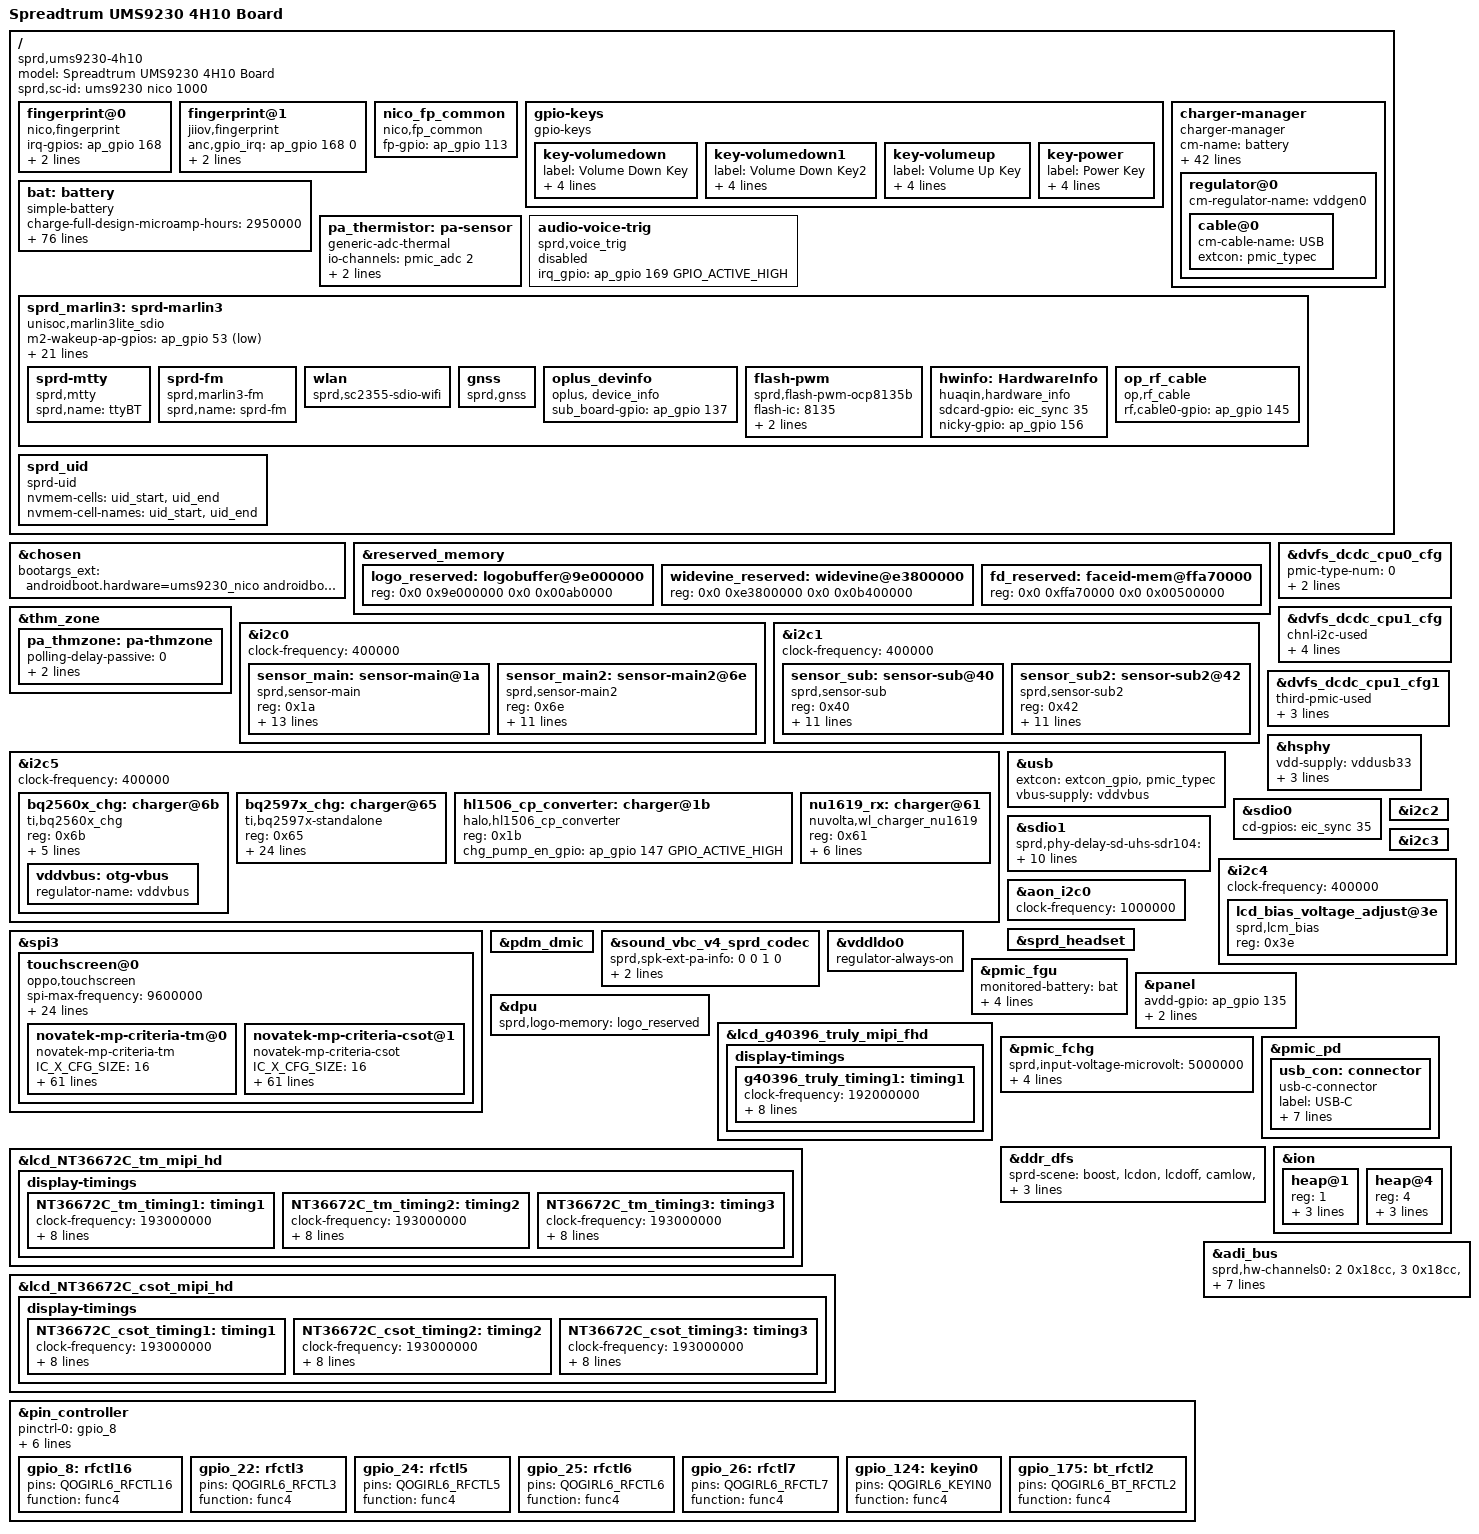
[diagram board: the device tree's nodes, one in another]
/dts-v1/;
/plugin/;
#include <dt-bindings/input/input.h>
#include <dt-bindings/gpio/gpio.h>
#include <dt-bindings/interrupt-controller/arm-gic.h>
#include <dt-bindings/clock/sprd,ums9230-clk.h>
#include <dt-bindings/mfd/sprd,sc2730-regs.h>
#include <dt-bindings/mfd/sprd,sc2730-mask.h>
#include <dt-bindings/usb/pd.h>
/*bsp.zhoulingyun 2022.04.04 modify for bring up lcd tm*/
#include "lcd/lcd_NT36672C_csot_mipi_hd.dtsi"
#include "lcd/lcd_NT36672C_tm_mipi_hd.dtsi"
#include "lcd/lcd_g40396_truly_mipi_fhd.dtsi"
#include "lcd/lcd_NT36672C_tm_mipi_hd_dummy.dtsi"
//#include "lcd/lcd_dummy_mipi.dtsi"

/ {

	model = "Spreadtrum UMS9230 4H10 Board";

	compatible = "sprd,ums9230-4h10";

	sprd,sc-id = "ums9230 nico 1000";
	fragment {
		target-path = "/";
		__overlay__ {
			#address-cells = <2>;
			#size-cells = <2>;
/*
			pwm_backlight: sprd_backlight {
				compatible = "sprd,sharkl6-backlight";
				pwms = <&pwms 2 40000>;
				pwm-names = "backlight";
				sprd,max-brightness-level = <924>;
				default-brightness-level = <262>;
				sprd,brightness-scale = <1023>;
				brightness-levels = <
							  0   3   4   5   6   7
					  8   9  10  11  12  13  14  16  17  18
					 19  20  21  22  23  24  25  26  27  28
					 29  31  33  35  37  39  41  43  45  47
					 48  50  52  54  56  58  60  62  64  67
					 69  72  74  76  78  80  82  84  86  88
					 90  92  94  96  98 100 102 104 107 109
					112 114 116 118 120 122 124 126 128 130
					132 134 136 138 140 142 144 147 149 151
					154 156 158 160 162 164 166 168 170 172
					175 178 181 184 187 190 193 196 199 203
					205 208 211 214 217 220 223 226 229 234
					237 240 243 247 250 253 256 259 263 266
					269 270 274 277 280 283 287 290 294 297
					300 303 307 310 314 318 325 329 334 339
					340 343 347 350 354 358 365 369 374 380
					382 385 389 392 396 400 407 411 416 422
					426 430 434 438 442 446 452 457 460 464
					470 474 480 486 492 498 504 508 512 516
					522 527 532 536 540 545 550 555 561 568
					574 579 584 589 594 600 605 610 615 620
					625 630 635 641 647 652 657 662 667 673
					688 694 700 706 712 716 720 725 730 735
					740 746 752 758 764 770 776 782 790 798
					803 810 817 825 832 840 845 850 855 861
					866 872 878 884 890 896 903 911 918 924
				>;
			};
*/
			fingerprint@0 {
				compatible = "nico,fingerprint";
				irq-gpios = <&ap_gpio 168 0 >;
				rst-gpios= <&ap_gpio 164 0 >;
				avdd-gpios = <&ap_gpio 122 0 >;
			};
			fingerprint@1 {
				compatible = "jiiov,fingerprint";
				anc,gpio_irq = <&ap_gpio 168 0>;
				anc,gpio_rst = <&ap_gpio 164 0>;
				anc,gpio_pwr = <&ap_gpio 122 0 >;
			}; 
			nico_fp_common {
				compatible = "nico,fp_common";
				fp-gpio = <&ap_gpio 113 0>;
			};
			gpio-keys {
				compatible = "gpio-keys";

				key-volumedown {
					label = "Volume Down Key";
					linux,code = <KEY_VOLUMEDOWN>;
					gpios = <&ap_gpio 124 GPIO_ACTIVE_LOW>;
					debounce-interval = <2>;
					wakeup-source;
				};

				key-volumedown1 {
					label = "Volume Down Key2";
					linux,code = <KEY_VOLUMEDOWN>;
					gpios = <&ap_gpio 125 GPIO_ACTIVE_LOW>;
					debounce-interval = <2>;
					wakeup-source;
				};

				key-volumeup {
					label = "Volume Up Key";
					linux,code = <KEY_VOLUMEUP>;
					gpios = <&pmic_eic 4 GPIO_ACTIVE_HIGH>;
					debounce-interval = <2>;
					wakeup-source;
				};

				key-power {
					label = "Power Key";
					linux,code = <KEY_POWER>;
					gpios = <&pmic_eic 1 GPIO_ACTIVE_LOW>;
					debounce-interval = <2>;
					wakeup-source;
				};
			};

			bat: battery {
				compatible = "simple-battery";
				charge-full-design-microamp-hours = <2950000>;
				charge-term-current-microamp = <60000>;
				constant-charge-voltage-max-microvolt = <4340000>;
				factory-internal-resistance-micro-ohms = <252000>;
				voltage-min-design-microvolt = <3450000>;
				fast-charge-threshold-microvolt = <4100000>;
				fullbatt-voltage = <4300000>;
				fullbatt-current = <120000>;
				fullbatt-track-end-vol = <4295000>;
				fullbatt-track-end-cur = <130000>;
				first-calib-voltage = <3580000>;
				first-calib-capacity = <50>;

				ir-cv-offset-microvolt = <100000>;
				ir-rc-micro-ohms = <20000>;
				ir-us-upper-limit-microvolt = <4500000>;

				ocv-capacity-celsius = <20>;
				ocv-capacity-table-0 = <4313000 100>, <4254000 95>, <4201000 90>,
							<4151000 85>, <4102000 80>, <4060000 75>,
							<4006000 70>, <3973000 65>, <3930000 60>,
							<3882000 55>, <3851000 50>, <3829000 45>,
							<3810000 40>, <3795000 35>, <3781000 30>,
							<3765000 25>, <3746000 20>, <3722000 15>,
							<3694000 10>, <3682000 5>, <3400000 0>;
				voltage-temp-table = <1084000 800>, <975000 850>, <868000 900>,
							  <765000 950>, <668000 1000>, <580000 1050>,
							  <501000 1100>, <430000 1150>, <369000 1200>,
							  <315000 1250>, <270000 1300>, <231000 1350>,
							  <197000 1400>, <169000 1450>, <145000 1500>,
							  <125000 1550>, <108000 1600>, <93000 1650>;
				capacity-temp-table = <45 100>, <25 100>, <10 100>, <0 95>, <(-10) 90>;
				resistance-temp-table = <45 53>, <25 100>, <10 395>, <0 567>, <(-10) 793>;
				charge-sdp-current-microamp = <500000 500000>;
				charge-dcp-current-microamp = <2000000 2500000>;
				charge-cdp-current-microamp = <1500000 1500000>;
				charge-unknown-current-microamp = <500000 500000>;
				charge-fchg-current-microamp = <3250000 3000000>;
				charge-flash-current-microamp = <5000000 2700000>;
				charge-wl-bpp-current-microamp = <1000000 1000000>;
				charge-wl-epp-current-microamp = <2000000 1000000>;

				dcp-jeita-temp-table = <1000 1030 0 4340000>, <1150 1180 700000 4340000>,
					<1450 1420 2000000 4340000>, <1600 1570 700000 4100000>;
				sdp-jeita-temp-table = <1000 1030 0 4340000>, <1150 1180 500000 4340000>,
					<1450 1420 500000 4340000>, <1600 1570 500000 4100000>;
				cdp-jeita-temp-table = <1000 1030 0 4340000>, <1150 1180 700000 4340000>,
					<1450 1420 1500000 4340000>, <1600 1570 700000 4100000>;
				unknown-jeita-temp-table = <1000 1030 0 4340000>, <1150 1180 500000 4340000>,
					<1450 1420 500000 4340000>, <1600 1570 500000 4100000>;
				fchg-jeita-temp-table = <1000 1030 0 4340000>, <1150 1180 700000 4340000>,
					<1450 1420 3250000 4340000>, <1600 1570 700000 4100000>;
				flash-jeita-temp-table = <1000 1030 0 4340000>, <1150 1180 1000000 4340000>,
					<1450 1420 5000000 4340000>, <1600 1570 1000000 4100000>;
				wl-bpp-jeita-temp-table = <1000 1030 0 4340000>, <1150 1180 500000 4340000>,
					<1450 1420 1000000 4340000>, <1600 1570 5000000 4100000>;
				wl-epp-jeita-temp-table = <1000 1030 0 4340000>, <1150 1180 500000 4340000>,
					<1450 1420 2000000 4340000>, <1600 1570 500000 4100000>;
				force-jeita-status = <2>;
			};

			charger-manager {
				compatible = "charger-manager";
				cm-name = "battery";
				cm-poll-mode = <2>;
				cm-poll-interval = <15000>;
				cm-battery-stat = <2>;

				cm-fullbatt-vchkdrop-ms = <30000>;
				cm-fullbatt-vchkdrop-volt = <60000>;
				cm-fullbatt-capacity = <100>;
				/*Charge pump target charge current*/
				cm-cp-taper-current = <1000000>;

				cm-num-chargers = <1>;
				cm-num-charge-pumps = <1>;
				cm-num-fast-chargers = <1>;
				cm-num-wireless-chargers = <1>;
				cm-num-wireless-charge-pump-converters = <1>;
				cm-chargers = "bq2560x_charger";
				cm-charge-pumps = "bq2597x-standalone";
				cm-fast-chargers = "sc2730_fast_charger";
				cm-wireless-chargers = "nu1619_wireless_charger";
				cm-wireless-charge-pump-converters = "hl1506_cp_converter";
				cm-fuel-gauge = "sc27xx-fgu";

				/* in deci centigrade */
				cm-battery-cold = <200>;
				cm-battery-cold-in-minus;
				cm-battery-hot = <800>;
				cm-battery-temp-diff = <100>;

				/* Allow charging for 6hr */
				cm-charging-max = <21600000>;
				/* recovery charging after stop charging 45min */
				cm-discharging-max = <2700000>;

				/* the interval to feed charger watchdog */
				cm-wdt-interval = <60>;

				/* drop voltage in microVolts to allow shutdown */
				cm-shutdown-voltage = <3100000>;

				/* when 99% of the time is exceeded, it will be forced to 100% */
				cm-tickle-time-out = <1500>;

				/* how much time to allow capacity change */
				cm-one-cap-time = <30>;
				/* cm-thermal-zone = "board-thmzone"; */
				/* when the safe charging voltage is exceeded, stop charging */
				cm-charge-voltage-max = <6500000>;
				cm-fast-charge-voltage-max = <10500000>;
				cm-flash-charge-voltage-max = <12000000>;
				cm-wireless-charge-voltage-max = <6500000>;
				cm-wireless-fast-charge-voltage-max = <12000000>;
				/* drop voltage in microVolts to restart charging */
				cm-charge-voltage-drop = <700000>;
				cm-fast-charge-voltage-drop = <700000>;
				cm-flash-charge-voltage-drop = <1000000>;
				cm-wireless-charge-voltage-drop = <700000>;
				cm-wireless-fast-charge-voltage-drop = <1000000>;

				cm-cap-remap-table = <1 2 3>, <2 3 2>, <98 99 2>, <99 100 3>;

				monitored-battery = <&bat>;

				regulator@0 {
					cm-regulator-name = "vddgen0";
					cable@0 {
						cm-cable-name = "USB";
						extcon = <&pmic_typec>;
					};
				};
			};
/*
			tboard_thermistor: thermal-sensor {
				compatible = "generic-adc-thermal";
				#thermal-sensor-cells = <0>;
				io-channels = <&pmic_adc 1>;
				io-channel-names = "sensor-channel";
				temperature-lookup-table = <
					(-39742) 1131
					(-29777) 1110
					(-19480) 1074
					(-4679) 983
					10110 838
					24805 654
					44922 413
					54903 316
					64895 238
					74884 178
					84883 133
					94883 100
					104880 75
					114889 57
					124872 43 >;
			};
*/
			pa_thermistor: pa-sensor {
				compatible = "generic-adc-thermal";
				#thermal-sensor-cells = <0>;
				io-channels = <&pmic_adc 2>;
				io-channel-names = "sensor-channel";
				temperature-lookup-table = <
					(-39742) 1131
					(-29777) 1110
					(-19480) 1074
					(-4679) 983
					10110 838
					24805 654
					44922 413
					54903 316
					64895 238
					74884 178
					84883 133
					94883 100
					104880 75
					114889 57
					124872 43 >;
			};
/*
			chg_thermistor: chg-sensor {
				compatible = "generic-adc-thermal";
				#thermal-sensor-cells = <0>;
				io-channels = <&pmic_adc 4>;
				io-channel-names = "sensor-channel";
				temperature-lookup-table = <
					(-39742) 1131
					(-29777) 1110
					(-19480) 1074
					(-4679) 983
					10110 838
					24805 654
					44922 413
					54903 316
					64895 238
					74884 178
					84883 133
					94883 100
					104880 75
					114889 57
					124872 43 >;
			};
*/
			audio-voice-trig {
				status = "disable";
				compatible = "sprd,voice_trig";
				irq_gpio = <&ap_gpio 169 GPIO_ACTIVE_HIGH>;
			};

			sprd_marlin3: sprd-marlin3 {
				compatible = "unisoc,marlin3lite_sdio";
				m2-wakeup-ap-gpios = <&ap_gpio 53 GPIO_ACTIVE_LOW>;
				reset-gpios = <&ap_gpio 177 GPIO_ACTIVE_LOW>;
				enable-gpios = <&ap_gpio 116 GPIO_ACTIVE_LOW>;
				m2-to-ap-irq-gpios = <&ap_gpio 52 GPIO_ACTIVE_LOW>;
				avdd12-supply = <&vddwcn>;
				avdd33-supply = <&vddwifipa>;
				dcxo18-supply = <&vddsim2>;
				xtal-26m-clk-type = "TSX";
				clock-names = "clk_32k","source","enable";
				clocks = <&aon_clk CLK_AUX2>,
					 <&ext_32k>,
					 <&aonapb_gate CLK_AUX2_EB>;

				extcon = <&sdio1>;
				sdhci-name = <&sdio1>;
				sprd,btwf-file-name = "/dev/block/by-name/wcnmodem";
				sprd,gnss-file-name = "/vendor/firmware/gnssmodem.bin";
				adma-tx;
				adma-rx;

				/*
				 * bound parameter:
				 * [0]:addr offset, [1]:mask, [2]:unboundval, [3]:boundval
				 */
				//avdd12-parent-bound-chip = <REG_ANA_SLP_DCDC_PD_CTRL MASK_ANA_SLP_DCDCGEN1_PD_EN 0x0 MASK_ANA_SLP_DCDCGEN1_PD_EN>;
				avdd12-bound-wbreq = <REG_ANA_LDO_XTL_EN10 MASK_ANA_LDO_VDDWCN_EXT_XTL3_EN 0x0 MASK_ANA_LDO_VDDWCN_EXT_XTL3_EN>;
				avdd33-bound-wbreq = <REG_ANA_LDO_XTL_EN11 MASK_ANA_LDO_VDDWIFIPA_EXT_XTL3_EN 0x0 MASK_ANA_LDO_VDDWIFIPA_EXT_XTL3_EN>;

				sprd-mtty {
					compatible = "sprd,mtty";
					sprd,name = "ttyBT";
				};

				sprd-fm {
					compatible = "sprd,marlin3-fm";
					sprd,name = "sprd-fm";
				};

				wlan {
					compatible = "sprd,sc2355-sdio-wifi";
				};

				gnss {
					compatible = "sprd,gnss";
				};

				/*Used to show hardware information for oplus factory mode*/
				oplus_devinfo:oplus_devinfo {
					compatible = "oplus, device_info";
					sub_board-gpio = <&ap_gpio 137 0>;
					status = "okay";
				};
				
				flash-pwm {
					compatible = "sprd,flash-pwm-ocp8135b";
					flash-ic = <8135>;
					pwms = <&pwms 0 50000>;
					flash-en-gpios = <&ap_gpio 139 0>;
					status = "okay";
				};
				
				/*Used to show hardware information for hq factory mode*/
				hwinfo:HardwareInfo {
					compatible = "huaqin,hardware_info";
					sdcard-gpio = <&eic_sync 35 0>;
					nicky-gpio  = <&ap_gpio 156 0>;
					status = "okay";
				};

				/*Used to check the RF antenna*/
				op_rf_cable {
					compatible = "op,rf_cable";
					status = "okay";
					rf,cable0-gpio = <&ap_gpio 145 0>;
				};
			};

			sprd_uid {
				compatible = "sprd-uid";
				nvmem-cells = <&uid_start>, <&uid_end>;
				nvmem-cell-names = "uid_start", "uid_end";
			};
		};
	};
};

&chosen {
	bootargs_ext = "androidboot.hardware=ums9230_nico androidboot.dtbo_idx=0";
};

&reserved_memory {
	#address-cells = <2>;
	#size-cells = <2>;
	logo_reserved: logobuffer@9e000000{
		reg = <0x0 0x9e000000 0x0 0x00ab0000>;
	};

	widevine_reserved: widevine@e3800000 {
		reg = <0x0 0xe3800000 0x0 0x0b400000>;
	};

	fd_reserved: faceid-mem@ffa70000 {
		reg = <0x0 0xffa70000 0x0 0x00500000>;
	};
};

&thm_zone {
/*
	bd_thmzone: board-thmzone {
		polling-delay-passive = <0>;
		polling-delay = <0>;
		thermal-sensors = <&tboard_thermistor>;
	};
*/
	pa_thmzone: pa-thmzone {
		polling-delay-passive = <0>;
		polling-delay = <0>;
		thermal-sensors = <&pa_thermistor>;
	};
/*
	chg_thmzone: chg-thmzone {
		polling-delay-passive = <0>;
		polling-delay = <0>;
		thermal-sensors = <&chg_thermistor>;
	};
*/
};

&i2c0 {
	status = "okay";
	clock-frequency = <400000>;
	#address-cells = <1>;
	#size-cells = <0>;

	sensor_main: sensor-main@1a {
		compatible = "sprd,sensor-main";
		reg = <0x1a>;
		clock-names = "clk_src","sensor_eb",
			"clk_96m","clk_76m8",
			"clk_48m","clk_26m";
		clocks = <&mm_clk CLK_SENSOR0>,<&mm_gate CLK_MM_SENSOR0_EB>,
				<&pll1 CLK_TWPLL_96M>,<&pll1 CLK_TWPLL_76M8>,
				<&pll1 CLK_TWPLL_48M>,<&ext_26m>;
		vddio-supply = <&vddcamio>;
		vddcama-supply = <&vddcama0>;
		vddcamd-supply = <&vddcamd0>;
		vddcammot-supply = <&vddcammot>;
		reset-gpios = <&ap_gpio 44 0>;
		dvdd-gpios = <&ap_gpio 82 0>;
		sprd,phyid = <2>;
		csi = <&csi0>;
		power-domains = <&mm_domain>;
	};

	sensor_main2: sensor-main2@6e {//macro
		compatible = "sprd,sensor-main2";
		reg = <0x6e>;
		clock-names = "clk_src","sensor_eb",
			"clk_96m","clk_76m8",
			"clk_48m","clk_26m";
		clocks = <&mm_clk CLK_SENSOR2>,<&mm_gate CLK_MM_SENSOR2_EB>,
				<&pll1 CLK_TWPLL_96M>,<&pll1 CLK_TWPLL_76M8>,
				<&pll1 CLK_TWPLL_48M>,<&ext_26m>;
		vddio-supply = <&vddcamio>;
		vddcama-supply = <&vddldo1>;
		sprd,vddldo1-voltage = <2800000>;
		reset-gpios = <&ap_gpio 45 0>;
		sprd,phyid = <4>;
		csi = <&csi1>;
		power-domains = <&mm_domain>;
		};
};

&i2c1 {
	status = "okay";
	clock-frequency = <400000>;
	#address-cells = <1>;
	#size-cells = <0>;

	sensor_sub: sensor-sub@40 {
		compatible = "sprd,sensor-sub";
		reg = <0x40>;
		clock-names = "clk_src","sensor_eb",
			"clk_96m","clk_76m8",
			"clk_48m","clk_26m";
		clocks = <&mm_clk CLK_SENSOR1>,<&mm_gate CLK_MM_SENSOR1_EB>,
				<&pll1 CLK_TWPLL_96M>,<&pll1 CLK_TWPLL_76M8>,
				<&pll1 CLK_TWPLL_48M>,<&ext_26m>;
		vddio-supply = <&vddcamio>;
		vddcama-supply = <&vddcama1>;
		vddcamd-supply = <&vddcamd1>;
	/*	dvdd-gpios = <&ap_gpio 137 0>;*/
	/*	vddcammot-supply = <&vddcammot>;*/
		reset-gpios = <&ap_gpio 41 0>;
	/*	power-down-gpios = <&ap_gpio 46 0>;*/
	/*	mipi-switch-en-gpios = <&ap_gpio 55 0>;*/
	/*	mipi-switch-mode-gpios = <&ap_gpio 8 0>;*/
		sprd,phyid = <0>;
		csi = <&csi0>;
		power-domains = <&mm_domain>;
	};

		sensor_sub2: sensor-sub2@42 {//vga
		compatible = "sprd,sensor-sub2";
		reg = <0x42>;
		clock-names = "clk_src","sensor_eb",
			"clk_96m","clk_76m8",
			"clk_48m","clk_26m";
		clocks = <&mm_clk CLK_SENSOR2>,<&mm_gate CLK_MM_SENSOR2_EB>,
				<&pll1 CLK_TWPLL_96M>,<&pll1 CLK_TWPLL_76M8>,
				<&pll1 CLK_TWPLL_48M>,<&ext_26m>;
		vddio-supply = <&vddcamio>;
		vddcama-supply = <&vddldo1>;
		sprd,vddldo1-voltage = <2800000>;
		reset-gpios = <&ap_gpio 40 0>;
		sprd,phyid = <3>;
		csi = <&csi1>;
		power-domains = <&mm_domain>;
	};
};

&i2c5 {
	status = "okay";
	clock-frequency = <400000>;
	#address-cells = <1>;
	#size-cells = <0>;

	bq2560x_chg: charger@6b {
		compatible = "ti,bq2560x_chg";
		reg = <0x6b>;
		phys = <&hsphy>;
		monitored-battery = <&bat>;
		extcon = <&pmic_typec>, <&pmic_pd>;
		pd-extcon-enable;
		irq-gpio = <&ap_gpio 115 GPIO_ACTIVE_LOW>;
		vddvbus:otg-vbus {
			regulator-name = "vddvbus";
		};
	};

	bq2597x_chg: charger@65 {
		compatible = "ti,bq2597x-standalone";
		reg = <0x65>;
		irq-gpio = <&ap_gpio 126 GPIO_ACTIVE_LOW>;

		ti,bq2597x,bus-therm-disable = <1>;
		ti,bq2597x,regulation-disable = <1>;

		ti,bq2597x,bat-ovp-threshold = <4400>;
		ti,bq2597x,bat-ovp-alarm-threshold = <4340>;
		ti,bq2597x,bat-ocp-threshold = <5500>;
		ti,bq2597x,bat-ocp-alarm-threshold = <5000>;
		ti,bq2597x,bus-ovp-threshold = <11500>;
		ti,bq2597x,bus-ovp-alarm-threshold = <10500>;
		ti,bq2597x,bus-ocp-threshold = <3000>;
		ti,bq2597x,bus-ocp-alarm-threshold = <2700>;
		ti,bq2597x,bat-ucp-alarm-threshold = <1000>;
		ti,bq2597x,bat-therm-threshold = <0x15>;
		ti,bq2597x,bus-therm-threshold = <0x15>;
		ti,bq2597x,die-therm-threshold = <0xc8>;
		ti,bq2597x,ac-ovp-threshold = <11>;
		ti,bq2597x,sense-resistor-mohm = <5>;
		ti,bq2597x,adc-sample-bits = <13>;
		ti,bq2597x,ibat-regulation-threshold = <300>;
		ti,bq2597x,vbat-regulation-threshold = <100>;
		ti,bq2597x,vdrop-threshold = <400>;
		ti,bq2597x,vdrop-deglitch = <5000>;
		ti,bq2597x,ss-timeout = <100000>;
		ti,bq2597x,watchdog-timer = <30000>;
	};

	hl1506_cp_converter: charger@1b {
		compatible = "halo,hl1506_cp_converter";
		reg = <0x1b>;
		chg_pump_en_gpio = <&ap_gpio 147 GPIO_ACTIVE_HIGH>;
	};

	nu1619_rx: charger@61 {
		compatible = "nuvolta,wl_charger_nu1619";
		reg = <0x61>;
		phys = <&hsphy>;
		rx,irq_gpio = <&ap_gpio 146 GPIO_ACTIVE_LOW>;
		switch_chg_en_gpio = <&ap_gpio 171 GPIO_ACTIVE_HIGH>;
		switch_flag_en_gpio = <&ap_gpio 176 GPIO_ACTIVE_HIGH>;
	};

};



&spi3 {
	status = "okay";
	#address-cells = <1>;
	#size-cells = <0>;


	touchscreen@0 {
			compatible = "oppo,touchscreen";
			spi-max-frequency = <9600000>;
			reg = <0>;
			/*touch,irq-gpio = <&ap_gpio 144 GPIO_ACTIVE_HIGH>;*/
			touch,irq-gpio = <&eic_async 16 GPIO_ACTIVE_HIGH>;
			touch,rst-gpio = <&ap_gpio 146 GPIO_ACTIVE_HIGH>;
			touch,panel-coords = <0 720 0 1600>;
			chipone,x-res = <720>;
			chipone,y-res = <1600>;

			chipone,test-reset-pin;
            chipone,test-rawdata;
            chipone,test-rawdata-frames = <1>;
            chipone,rawdata-min = <1500>;//base 2500*40%
            chipone,rawdata-max = <3500>;
            chipone,test-noise;
            chipone,test-noise-frames = <50>;
            chipone,noise-max = <70>;
            chipone,test-open;
            chipone,open-min = <3000>;
            chipone,test-short;
            chipone,short-min = <500>;
            chipone,test-compensate-cap;
            chipone,compensate-cap-min = <1>;
            chipone,compensate-cap-max = <126>;
			himax,display-coords = <0 720 0 1600>;

		//for novatek
		//novatek,pen-support;
		//novatek,stylus-resol-double;

		/* 525 */
		//novatek,swrst-n8-addr = <0x01F01A>;

		/* 672A, 525B, 675, 526, 672C, 523 */
		novatek,swrst-n8-addr = <0x03F0FE>;
		//novatek,spi-rd-fast-addr = <0x03F310>;

		/* MP */
		novatek,mp-support-dt;

		/* MP Criteria For TM */
		novatek-mp-criteria-tm@0 {
			#address-cells = <1>;
			#size-cells = <0>;
			compatible = "novatek-mp-criteria-tm";

			/* MP Config */
			IC_X_CFG_SIZE = <16>;
			IC_Y_CFG_SIZE = <36>;
			IC_KEY_CFG_SIZE = <4>;
			X_Channel = <16>;
			Y_Channel = <36>;
			AIN_X = <0 1 2 3 4 5 6 7 8 9 10 11 12 13 14 15>;
			AIN_Y = <0 1 2 3 4 5 6 7 8 9 10 11 12 13 14 15 16 17 18 19 20 21 22 23 24 25 26 27 28 29 30 31 32 33 34 35>;
			AIN_KEY = <0 1 2 0xFF>;

			/* MP Criteria */
			PS_Config_Lmt_Short_Rawdata_P = <
				14008 14008 14008 14008 14008 14008 14008 14008 14008 14008 14008 14008 14008 14008 14008 14008
				14008 14008 14008 14008 14008 14008 14008 14008 14008 14008 14008 14008 14008 14008 14008 14008
				14008 14008 14008 14008 14008 14008 14008 14008 14008 14008 14008 14008 14008 14008 14008 14008
				14008 14008 14008 14008 14008 14008 14008 14008 14008 14008 14008 14008 14008 14008 14008 14008
				14008 14008 14008 14008 14008 14008 14008 14008 14008 14008 14008 14008 14008 14008 14008 14008
				14008 14008 14008 14008 14008 14008 14008 14008 14008 14008 14008 14008 14008 14008 14008 14008
				14008 14008 14008 14008 14008 14008 14008 14008 14008 14008 14008 14008 14008 14008 14008 14008
				14008 14008 14008 14008 14008 14008 14008 14008 14008 14008 14008 14008 14008 14008 14008 14008
				14008 14008 14008 14008 14008 14008 14008 14008 14008 14008 14008 14008 14008 14008 14008 14008
				14008 14008 14008 14008 14008 14008 14008 14008 14008 14008 14008 14008 14008 14008 14008 14008
				14008 14008 14008 14008 14008 14008 14008 14008 14008 14008 14008 14008 14008 14008 14008 14008
				14008 14008 14008 14008 14008 14008 14008 14008 14008 14008 14008 14008 14008 14008 14008 14008
				14008 14008 14008 14008 14008 14008 14008 14008 14008 14008 14008 14008 14008 14008 14008 14008
				14008 14008 14008 14008 14008 14008 14008 14008 14008 14008 14008 14008 14008 14008 14008 14008
				14008 14008 14008 14008 14008 14008 14008 14008 14008 14008 14008 14008 14008 14008 14008 14008
				14008 14008 14008 14008 14008 14008 14008 14008 14008 14008 14008 14008 14008 14008 14008 14008
				14008 14008 14008 14008 14008 14008 14008 14008 14008 14008 14008 14008 14008 14008 14008 14008
				14008 14008 14008 14008 14008 14008 14008 14008 14008 14008 14008 14008 14008 14008 14008 14008
				14008 14008 14008 14008 14008 14008 14008 14008 14008 14008 14008 14008 14008 14008 14008 14008
				14008 14008 14008 14008 14008 14008 14008 14008 14008 14008 14008 14008 14008 14008 14008 14008
				14008 14008 14008 14008 14008 14008 14008 14008 14008 14008 14008 14008 14008 14008 14008 14008
				14008 14008 14008 14008 14008 14008 14008 14008 14008 14008 14008 14008 14008 14008 14008 14008
				14008 14008 14008 14008 14008 14008 14008 14008 14008 14008 14008 14008 14008 14008 14008 14008
				14008 14008 14008 14008 14008 14008 14008 14008 14008 14008 14008 14008 14008 14008 14008 14008
				14008 14008 14008 14008 14008 14008 14008 14008 14008 14008 14008 14008 14008 14008 14008 14008
				14008 14008 14008 14008 14008 14008 14008 14008 14008 14008 14008 14008 14008 14008 14008 14008
				14008 14008 14008 14008 14008 14008 14008 14008 14008 14008 14008 14008 14008 14008 14008 14008
				14008 14008 14008 14008 14008 14008 14008 14008 14008 14008 14008 14008 14008 14008 14008 14008
				14008 14008 14008 14008 14008 14008 14008 14008 14008 14008 14008 14008 14008 14008 14008 14008
				14008 14008 14008 14008 14008 14008 14008 14008 14008 14008 14008 14008 14008 14008 14008 14008
				14008 14008 14008 14008 14008 14008 14008 14008 14008 14008 14008 14008 14008 14008 14008 14008
				14008 14008 14008 14008 14008 14008 14008 14008 14008 14008 14008 14008 14008 14008 14008 14008
				14008 14008 14008 14008 14008 14008 14008 14008 14008 14008 14008 14008 14008 14008 14008 14008
				14008 14008 14008 14008 14008 14008 14008 14008 14008 14008 14008 14008 14008 14008 14008 14008
				14008 14008 14008 14008 14008 14008 14008 14008 14008 14008 14008 14008 14008 14008 14008 14008
				14008 14008 14008 14008 14008 14008 14008 14008 14008 14008 14008 14008 14008 14008 14008 14008
				>;

			PS_Config_Lmt_Short_Rawdata_N = <
				10100 10100 10100 10100 10100 10100 10100 10100 10100 10100 10100 10100 10100 10100 10100 10100
				10100 10100 10100 10100 10100 10100 10100 10100 10100 10100 10100 10100 10100 10100 10100 10100
				10100 10100 10100 10100 10100 10100 10100 10100 10100 10100 10100 10100 10100 10100 10100 10100
				10100 10100 10100 10100 10100 10100 10100 10100 10100 10100 10100 10100 10100 10100 10100 10100
				10100 10100 10100 10100 10100 10100 10100 10100 10100 10100 10100 10100 10100 10100 10100 10100
				10100 10100 10100 10100 10100 10100 10100 10100 10100 10100 10100 10100 10100 10100 10100 10100
				10100 10100 10100 10100 10100 10100 10100 10100 10100 10100 10100 10100 10100 10100 10100 10100
				10100 10100 10100 10100 10100 10100 10100 10100 10100 10100 10100 10100 10100 10100 10100 10100
				10100 10100 10100 10100 10100 10100 10100 10100 10100 10100 10100 10100 10100 10100 10100 10100
				10100 10100 10100 10100 10100 10100 10100 10100 10100 10100 10100 10100 10100 10100 10100 10100
				10100 10100 10100 10100 10100 10100 10100 10100 10100 10100 10100 10100 10100 10100 10100 10100
				10100 10100 10100 10100 10100 10100 10100 10100 10100 10100 10100 10100 10100 10100 10100 10100
				10100 10100 10100 10100 10100 10100 10100 10100 10100 10100 10100 10100 10100 10100 10100 10100
				10100 10100 10100 10100 10100 10100 10100 10100 10100 10100 10100 10100 10100 10100 10100 10100
				10100 10100 10100 10100 10100 10100 10100 10100 10100 10100 10100 10100 10100 10100 10100 10100
				10100 10100 10100 10100 10100 10100 10100 10100 10100 10100 10100 10100 10100 10100 10100 10100
				10100 10100 10100 10100 10100 10100 10100 10100 10100 10100 10100 10100 10100 10100 10100 10100
				10100 10100 10100 10100 10100 10100 10100 10100 10100 10100 10100 10100 10100 10100 10100 10100
				10100 10100 10100 10100 10100 10100 10100 10100 10100 10100 10100 10100 10100 10100 10100 10100
				10100 10100 10100 10100 10100 10100 10100 10100 10100 10100 10100 10100 10100 10100 10100 10100
				10100 10100 10100 10100 10100 10100 10100 10100 10100 10100 10100 10100 10100 10100 10100 10100
				10100 10100 10100 10100 10100 10100 10100 10100 10100 10100 10100 10100 10100 10100 10100 10100
				10100 10100 10100 10100 10100 10100 10100 10100 10100 10100 10100 10100 10100 10100 10100 10100
				10100 10100 10100 10100 10100 10100 10100 10100 10100 10100 10100 10100 10100 10100 10100 10100
				10100 10100 10100 10100 10100 10100 10100 10100 10100 10100 10100 10100 10100 10100 10100 10100
				10100 10100 10100 10100 10100 10100 10100 10100 10100 10100 10100 10100 10100 10100 10100 10100
				10100 10100 10100 10100 10100 10100 10100 10100 10100 10100 10100 10100 10100 10100 10100 10100
				10100 10100 10100 10100 10100 10100 10100 10100 10100 10100 10100 10100 10100 10100 10100 10100
				10100 10100 10100 10100 10100 10100 10100 10100 10100 10100 10100 10100 10100 10100 10100 10100
				10100 10100 10100 10100 10100 10100 10100 10100 10100 10100 10100 10100 10100 10100 10100 10100
				10100 10100 10100 10100 10100 10100 10100 10100 10100 10100 10100 10100 10100 10100 10100 10100
				10100 10100 10100 10100 10100 10100 10100 10100 10100 10100 10100 10100 10100 10100 10100 10100
				10100 10100 10100 10100 10100 10100 10100 10100 10100 10100 10100 10100 10100 10100 10100 10100
				10100 10100 10100 10100 10100 10100 10100 10100 10100 10100 10100 10100 10100 10100 10100 10100
				10100 10100 10100 10100 10100 10100 10100 10100 10100 10100 10100 10100 10100 10100 10100 10100
				10100 10100 10100 10100 10100 10100 10100 10100 10100 10100 10100 10100 10100 10100 10100 10100
				>;

			PS_Config_Lmt_Open_Rawdata_P = <
				1692 1716 1733 1752 1741 1741 1726 65535 65535 1675 1687 1703 1717 1717 1696 1696
				1670 1687 1709 1736 1730 1727 1726 1694 1642 1696 1691 1708 1722 1715 1691 1702
				1652 1681 1702 1731 1727 1723 1724 1706 1664 1712 1712 1727 1745 1730 1712 1722
				1709 1720 1750 1785 1778 1773 1775 1755 1705 1734 1730 1747 1759 1741 1722 1730
				1754 1752 1787 1825 1814 1811 1808 1792 1769 1785 1792 1811 1817 1800 1782 1794
				1758 1772 1789 1825 1817 1815 1813 1794 1752 1785 1769 1790 1796 1778 1759 1772
				1776 1793 1810 1842 1836 1836 1828 1814 1750 1779 1766 1783 1783 1772 1747 1768
				1800 1822 1825 1870 1869 1870 1862 1845 1804 1834 1806 1835 1831 1814 1790 1807
				1807 1825 1846 1869 1873 1870 1862 1842 1825 1852 1841 1849 1839 1825 1804 1820
				1836 1860 1877 1888 1906 1905 1899 1871 1838 1866 1852 1848 1849 1834 1807 1829
				1856 1878 1895 1926 1919 1923 1911 1890 1864 1897 1884 1898 1873 1862 1832 1856
				1873 1902 1916 1946 1927 1944 1932 1905 1894 1926 1909 1925 1880 1881 1853 1874
				1864 1892 1908 1937 1940 1940 1926 1898 1880 1909 1898 1909 1878 1867 1838 1862
				1869 1899 1922 1947 1954 1948 1936 1904 1881 1909 1898 1911 1876 1856 1832 1859
				1897 1927 1943 1968 1974 1957 1954 1922 1927 1954 1939 1957 1922 1888 1874 1901
				1913 1948 1962 1989 2000 1997 1979 1946 1955 1976 1962 1978 1937 1916 1884 1906
				1913 1948 1953 1983 1995 1996 1957 1940 1944 1972 1955 1975 1933 1918 1866 1916
				1933 1974 1979 2007 2023 2024 2007 1965 1989 2016 1997 2014 1971 1951 1915 1946
				1958 1927 1919 1922 1897 1894 1883 1877 1838 1901 1890 1898 1898 1911 1902 1919
				1974 1947 1934 1939 1916 1915 1902 1887 1866 1929 1918 1932 1930 1943 1932 1937
				1972 1951 1941 1947 1926 1922 1912 1909 1856 1912 1906 1920 1918 1934 1919 1930
				1981 1961 1953 1958 1933 1929 1920 1912 1883 1941 1936 1948 1946 1960 1947 1958
				1993 1982 1968 1971 1953 1944 1930 1926 1899 1957 1947 1967 1964 1974 1958 1971
				1999 1989 1979 1986 1960 1955 1944 1939 1890 1943 1940 1958 1955 1962 1950 1964
				1983 1978 1967 1975 1950 1943 1930 1923 1898 1953 1946 1965 1962 1974 1960 1974
				2030 2027 2013 2021 1999 1995 1981 1975 1908 1957 1951 1971 1968 1979 1962 1972
				2002 2002 1992 2002 1974 1969 1957 1950 1894 1944 1939 1958 1955 1964 1954 1958
				2014 2018 2013 2021 1995 1993 1983 1976 1926 1974 1967 1988 1982 1996 1981 1986
				2030 2041 2027 2041 2007 2004 1990 1981 1940 1990 1982 2007 2000 2014 1999 2006
				2025 2034 2027 2039 2009 2007 1996 1983 1943 1990 1982 2004 1999 2013 1996 2003
				2016 2037 2025 2032 2003 2000 1988 1976 1912 1964 1958 1975 1971 1988 1965 1972
				2044 2066 2058 2066 2038 2041 2023 2010 1964 2016 2003 2024 2020 2037 2014 2018
				2017 2038 2035 2042 2017 2016 1999 1985 1939 1988 1978 1996 1992 2006 1981 1988
				2025 2049 2046 2058 2028 2031 2014 1999 1969 2017 2002 2023 2016 2031 2002 2010
				1978 2021 2020 2032 2002 2003 1988 1972 1948 1997 1981 2004 1999 2016 1982 1978
				1820 1876 1971 2052 2020 2020 2002 1986 1974 2027 2010 2035 2032 1988 1867 1829
				>;

			PS_Config_Lmt_Open_Rawdata_N = <
				725 735 742 751 746 746 739 (-65535) (-65535) 718 723 730 736 736 727 727
				715 723 732 744 741 740 739 726 703 727 724 732 738 735 724 729
				708 720 729 742 740 738 739 731 713 733 733 740 748 741 733 738
				732 737 750 765 762 760 760 752 730 743 741 748 754 746 738 741
				751 751 766 782 777 776 775 768 758 765 768 776 778 771 763 769
				753 759 766 782 778 778 777 769 751 765 758 767 769 762 754 759
				761 768 775 789 787 787 783 777 750 762 757 764 764 759 748 757
				771 781 782 801 801 801 798 790 773 786 774 786 784 777 767 774
				774 782 791 801 802 801 798 789 782 793 789 792 788 782 773 780
				787 797 804 809 817 816 814 802 787 799 793 792 792 786 774 784
				795 805 812 825 822 824 819 810 799 813 807 813 802 798 785 795
				802 815 821 834 826 833 828 816 811 825 818 825 805 806 794 803
				799 811 817 830 831 831 825 813 805 818 813 818 805 800 787 798
				801 814 823 834 837 835 829 816 806 818 813 819 804 795 785 796
				813 826 832 843 846 838 837 823 826 837 831 838 823 809 803 814
				820 835 841 852 857 856 848 834 838 847 841 847 830 821 807 817
				820 835 837 850 855 855 838 831 833 845 838 846 828 822 799 821
				828 846 848 860 867 867 860 842 852 864 856 863 844 836 820 834
				839 826 822 823 813 811 807 804 787 814 810 813 813 819 815 822
				846 834 829 831 821 820 815 808 799 826 822 828 827 832 828 830
				845 836 832 834 825 823 819 818 795 819 817 823 822 829 822 827
				849 840 837 839 828 826 823 819 807 832 829 835 834 840 834 839
				854 849 843 844 837 833 827 825 814 838 834 843 841 846 839 844
				856 852 848 851 840 838 833 831 810 832 831 839 838 841 835 841
				850 847 843 846 835 832 827 824 813 837 834 842 841 846 840 846
				870 868 862 866 856 855 849 846 817 838 836 844 843 848 841 845
				858 858 853 858 846 844 838 835 811 833 831 839 838 841 837 839
				863 865 862 866 855 854 850 847 825 846 843 852 849 855 849 851
				870 874 868 874 860 859 853 849 831 853 849 860 857 863 856 859
				868 871 868 874 861 860 855 850 832 853 849 859 856 862 855 858
				864 873 868 871 858 857 852 847 819 841 839 846 844 852 842 845
				876 885 882 885 873 874 867 861 841 864 858 867 865 873 863 865
				864 873 872 875 864 864 856 850 831 852 847 855 853 859 849 852
				868 878 877 882 869 870 863 856 844 864 858 867 864 870 858 861
				847 866 865 871 858 858 852 845 835 856 849 859 856 864 849 847
				780 804 844 879 865 865 858 851 846 868 861 872 871 852 800 784
				>;

			PS_Config_Lmt_FW_Rawdata_P = <
				1138 1120 1107 1107 1108 1100 1111 65535 65535 1125 1107 1120 1111 1103 1107 1125
				1113 1110 1106 1103 1118 1107 1115 1115 1121 1107 1107 1107 1111 1108 1107 1127
				1118 1111 1110 1114 1093 1108 1103 1110 1120 1115 1114 1106 1115 1113 1110 1124
				1122 1090 1096 1100 1090 1092 1089 1104 1115 1118 1113 1104 1108 1111 1110 1110
				1113 1108 1108 1121 1104 1111 1107 1106 1099 1100 1096 1094 1097 1099 1099 1108
				1103 1108 1111 1090 1111 1103 1106 1097 1114 1111 1108 1107 1121 1118 1121 1092
				1114 1110 1118 1124 1114 1128 1118 1122 1111 1111 1115 1113 1122 1124 1121 1110
				1134 1100 1101 1106 1101 1106 1100 1121 1107 1108 1114 1115 1117 1111 1115 1110
				1090 1076 1089 1080 1096 1090 1096 1086 1108 1111 1124 1120 1117 1117 1117 1099
				1107 1129 1125 1125 1124 1117 1131 1106 1142 1135 1122 1125 1117 1114 1120 1108
				1115 1106 1120 1129 1106 1118 1106 1108 1099 1103 1107 1099 1099 1090 1097 1115
				1101 1122 1115 1122 1100 1121 1110 1103 1113 1117 1110 1108 1107 1104 1110 1124
				1128 1134 1131 1128 1121 1129 1121 1120 1120 1121 1117 1114 1113 1114 1107 1114
				1113 1097 1101 1113 1103 1111 1115 1113 1108 1101 1093 1100 1110 1099 1087 1103
				1121 1120 1106 1117 1118 1115 1110 1113 1085 1079 1122 1100 1086 1110 1104 1094
				1113 1096 1107 1117 1114 1108 1117 1110 1103 1101 1097 1094 1097 1094 1100 1117
				1103 1104 1094 1093 1097 1103 1094 1113 1113 1118 1121 1115 1107 1096 1085 1136
				1099 1104 1118 1100 1100 1108 1107 1136 1111 1107 1103 1107 1122 1114 1113 1122
				1101 1110 1115 1107 1113 1106 1101 1097 1108 1103 1092 1100 1092 1086 1120 1107
				1124 1110 1114 1114 1114 1111 1118 1124 1101 1115 1120 1111 1118 1122 1115 1094
				1108 1117 1115 1121 1120 1118 1113 1114 1111 1117 1107 1110 1110 1103 1103 1108
				1117 1110 1104 1103 1104 1101 1108 1110 1120 1103 1096 1106 1106 1114 1094 1118
				1114 1120 1125 1129 1111 1110 1114 1115 1124 1121 1120 1118 1124 1121 1131 1115
				1115 1118 1113 1115 1110 1113 1120 1115 1092 1107 1103 1107 1113 1111 1108 1111
				1094 1108 1114 1111 1108 1114 1093 1099 1094 1103 1097 1100 1101 1090 1094 1135
				1104 1124 1113 1111 1093 1089 1100 1100 1090 1124 1124 1122 1114 1090 1093 1122
				1108 1118 1114 1107 1115 1106 1106 1108 1120 1120 1114 1120 1118 1120 1120 1118
				1114 1131 1136 1127 1128 1122 1132 1134 1110 1124 1125 1125 1128 1113 1111 1114
				1115 1103 1101 1103 1099 1108 1103 1106 1111 1113 1118 1127 1121 1113 1118 1110
				1122 1118 1115 1099 1099 1093 1104 1104 1104 1108 1100 1103 1096 1110 1110 1125
				1118 1117 1114 1113 1107 1099 1093 1103 1121 1125 1121 1121 1114 1110 1111 1118
				1132 1108 1111 1104 1110 1099 1108 1107 1129 1118 1127 1113 1111 1117 1118 1092
				1128 1097 1101 1096 1103 1106 1082 1099 1108 1121 1107 1113 1115 1122 1118 1111
				1115 1113 1117 1107 1101 1096 1097 1107 1113 1103 1093 1096 1097 1114 1108 1134
				1142 1129 1136 1120 1117 1108 1120 1114 1129 1127 1125 1136 1128 1100 1127 1086
				1107 1100 1100 1104 1104 1108 1111 1117 1135 1128 1117 1120 1110 1106 1100 1104
				>;

			PS_Config_Lmt_FW_Rawdata_N = <
				487 480 474 474 475 471 476 (-65535) (-65535) 482 474 480 476 472 474 482
				477 475 474 472 479 474 478 478 480 474 474 474 476 475 474 483
				479 476 475 477 468 475 472 475 480 478 477 474 478 477 475 481
				481 467 469 471 467 468 466 473 478 479 477 473 475 476 475 475
				477 475 475 480 473 476 474 474 471 471 469 469 470 471 471 475
				472 475 476 467 476 472 474 470 477 476 475 474 480 479 480 468
				477 475 479 481 477 483 479 481 476 476 478 477 481 481 480 475
				486 471 472 474 472 474 471 480 474 475 477 478 478 476 478 475
				467 461 466 463 469 467 469 465 475 476 481 480 478 478 478 471
				474 484 482 482 481 478 484 474 489 486 481 482 478 477 480 475
				478 474 480 484 474 479 474 475 471 472 474 471 471 467 470 478
				472 481 478 481 471 480 475 472 477 478 475 475 474 473 475 481
				483 486 484 483 480 484 480 480 480 480 478 477 477 477 474 477
				477 470 472 477 472 476 478 477 475 472 468 471 475 471 466 472
				480 480 474 478 479 478 475 477 465 462 481 471 465 475 473 469
				477 469 474 478 477 475 478 475 472 472 470 469 470 469 471 478
				472 473 469 468 470 472 469 477 477 479 480 478 474 469 465 487
				471 473 479 471 471 475 474 487 476 474 472 474 481 477 477 481
				472 475 478 474 477 474 472 470 475 472 468 471 468 465 480 474
				481 475 477 477 477 476 479 481 472 478 480 476 479 481 478 469
				475 478 478 480 480 479 477 477 476 478 474 475 475 472 472 475
				478 475 473 472 473 472 475 475 480 472 469 474 474 477 469 479
				477 480 482 484 476 475 477 478 481 480 480 479 481 480 484 478
				478 479 477 478 475 477 480 478 468 474 472 474 477 476 475 476
				469 475 477 476 475 477 468 471 469 472 470 471 472 467 469 486
				473 481 477 476 468 466 471 471 467 481 481 481 477 467 468 481
				475 479 477 474 478 474 474 475 480 480 477 480 479 480 480 479
				477 484 487 483 483 481 485 486 475 481 482 482 483 477 476 477
				478 472 472 472 471 475 472 474 476 477 479 483 480 477 479 475
				481 479 478 471 471 468 473 473 473 475 471 472 469 475 475 482
				479 478 477 477 474 471 468 472 480 482 480 480 477 475 476 479
				485 475 476 473 475 471 475 474 484 479 483 477 476 478 479 468
				483 470 472 469 472 474 463 471 475 480 474 477 478 481 479 476
				478 477 478 474 472 469 470 474 477 472 468 469 470 477 475 486
				489 484 487 480 478 475 480 477 484 483 482 487 483 471 483 465
				474 471 471 473 473 475 476 478 486 483 478 480 475 474 471 473
				>;

			PS_Config_Lmt_FW_CC_P = <
				41 41 41 42 41 42 41 65535 65535 41 42 41 42 42 41 41
				42 41 41 41 41 41 41 42 41 41 41 41 41 41 41 41
				41 41 41 41 41 41 41 41 41 41 41 41 41 41 41 41
				42 42 42 42 42 42 42 42 41 41 41 41 41 41 41 42
				42 41 41 41 41 41 41 41 41 41 41 42 41 41 41 42
				42 41 41 42 41 42 41 42 41 41 41 41 41 41 41 42
				42 41 41 41 41 41 41 41 41 41 41 41 41 41 41 42
				42 42 42 42 42 42 42 42 41 41 41 41 41 41 41 42
				42 41 41 42 41 41 41 41 42 42 41 41 42 42 42 42
				42 42 42 42 42 42 42 42 41 41 41 41 41 41 41 42
				42 42 42 42 42 42 42 42 42 42 41 41 42 42 42 42
				42 42 42 42 42 42 42 44 42 42 41 42 42 42 41 42
				42 41 41 42 41 42 42 42 42 42 41 42 42 42 42 42
				42 42 42 42 42 42 42 42 42 42 42 42 42 41 41 42
				42 41 42 42 42 42 42 42 42 42 41 42 42 41 41 42
				42 42 42 42 42 42 42 44 42 42 42 42 42 42 42 42
				42 41 42 42 42 42 42 42 42 42 42 42 42 42 42 42
				42 42 42 42 42 42 42 44 42 42 42 42 41 41 41 42
				42 41 41 41 41 41 41 41 42 42 42 41 42 42 41 42
				44 42 42 42 42 42 42 42 42 42 42 42 42 42 41 42
				42 41 41 41 41 41 41 41 42 41 41 41 41 41 41 42
				44 42 42 42 42 42 42 42 42 42 42 41 42 41 41 42
				42 42 41 41 41 41 41 41 42 42 42 42 42 42 42 42
				44 42 42 42 42 42 42 42 42 42 42 42 42 42 42 42
				42 42 41 41 41 41 41 41 42 42 42 42 42 42 42 42
				44 42 42 42 42 42 42 42 42 42 42 41 42 42 42 42
				42 42 42 42 41 41 41 41 41 41 42 41 42 42 42 42
				44 42 42 42 42 42 42 42 42 41 41 41 41 42 42 42
				42 42 42 42 42 42 42 42 41 42 42 42 42 42 42 42
				44 42 42 42 42 42 42 42 42 41 41 41 42 42 42 42
				42 42 42 41 41 41 41 41 41 41 41 41 42 42 42 42
				44 42 42 42 42 42 42 42 42 42 41 42 42 42 42 44
				42 42 42 42 42 42 42 42 41 42 41 42 42 42 42 42
				44 42 42 42 42 42 42 42 42 42 42 42 42 42 42 42
				42 42 42 41 41 41 41 41 41 42 41 41 41 42 42 42
				42 42 42 42 42 42 42 44 42 42 42 42 42 42 42 42
				>;

			PS_Config_Lmt_FW_CC_N = <
				18 18 18 19 18 19 18 (-65535) (-65535) 18 19 18 19 19 18 18
				19 18 18 18 18 18 18 19 18 18 18 18 18 18 18 18
				18 18 18 18 18 18 18 18 18 18 18 18 18 18 18 18
				19 19 19 19 19 19 19 19 18 18 18 18 18 18 18 19
				19 18 18 18 18 18 18 18 18 18 18 19 18 18 18 19
				19 18 18 19 18 19 18 19 18 18 18 18 18 18 18 19
				19 18 18 18 18 18 18 18 18 18 18 18 18 18 18 19
				19 19 19 19 19 19 19 19 18 18 18 18 18 18 18 19
				19 18 18 19 18 18 18 18 19 19 18 18 19 19 19 19
				19 19 19 19 19 19 19 19 18 18 18 18 18 18 18 19
				19 19 19 19 19 19 19 19 19 19 18 18 19 19 19 19
				19 19 19 19 19 19 19 19 19 19 18 19 19 19 18 19
				19 18 18 19 18 19 19 19 19 19 18 19 19 19 19 19
				19 19 19 19 19 19 19 19 19 19 19 19 19 18 18 19
				19 18 19 19 19 19 19 19 19 19 18 19 19 18 18 19
				19 19 19 19 19 19 19 19 19 19 19 19 19 19 19 19
				19 18 19 19 19 19 19 19 19 19 19 19 19 19 19 19
				19 19 19 19 19 19 19 19 19 19 19 19 18 18 18 19
				19 18 18 18 18 18 18 18 19 19 19 18 19 19 18 19
				19 19 19 19 19 19 19 19 19 19 19 19 19 19 18 19
				19 18 18 18 18 18 18 18 19 18 18 18 18 18 18 19
				19 19 19 19 19 19 19 19 19 19 19 18 19 18 18 19
				19 19 18 18 18 18 18 18 19 19 19 19 19 19 19 19
				19 19 19 19 19 19 19 19 19 19 19 19 19 19 19 19
				19 19 18 18 18 18 18 18 19 19 19 19 19 19 19 19
				19 19 19 19 19 19 19 19 19 19 19 18 19 19 19 19
				19 19 19 19 18 18 18 18 18 18 19 18 19 19 19 19
				19 19 19 19 19 19 19 19 19 18 18 18 18 19 19 19
				19 19 19 19 19 19 19 19 18 19 19 19 19 19 19 19
				19 19 19 19 19 19 19 19 19 18 18 18 19 19 19 19
				19 19 19 18 18 18 18 18 18 18 18 18 19 19 19 19
				19 19 19 19 19 19 19 19 19 19 18 19 19 19 19 19
				19 19 19 19 19 19 19 19 18 19 18 19 19 19 19 19
				19 19 19 19 19 19 19 19 19 19 19 19 19 19 19 19
				19 19 19 18 18 18 18 18 18 19 18 18 18 19 19 19
				19 19 19 19 19 19 19 19 19 19 19 19 19 19 19 19
				>;

			PS_Config_Lmt_FW_Diff_P = <
				50 50 50 50 50 50 50 65535 65535 50 50 50 50 50 50 50
				50 50 50 50 50 50 50 50 50 50 50 50 50 50 50 50
				50 50 50 50 50 50 50 50 50 50 50 50 50 50 50 50
				50 50 50 50 50 50 50 50 50 50 50 50 50 50 50 50
				50 50 50 50 50 50 50 50 50 50 50 50 50 50 50 50
				50 50 50 50 50 50 50 50 50 50 50 50 50 50 50 50
				50 50 50 50 50 50 50 50 50 50 50 50 50 50 50 50
				50 50 50 50 50 50 50 50 50 50 50 50 50 50 50 50
				50 50 50 50 50 50 50 50 50 50 50 50 50 50 50 50
				50 50 50 50 50 50 50 50 50 50 50 50 50 50 50 50
				50 50 50 50 50 50 50 50 50 50 50 50 50 50 50 50
				50 50 50 50 50 50 50 50 50 50 50 50 50 50 50 50
				50 50 50 50 50 50 50 50 50 50 50 50 50 50 50 50
				50 50 50 50 50 50 50 50 50 50 50 50 50 50 50 50
				50 50 50 50 50 50 50 50 50 50 50 50 50 50 50 50
				50 50 50 50 50 50 50 50 50 50 50 50 50 50 50 50
				50 50 50 50 50 50 50 50 50 50 50 50 50 50 50 50
				50 50 50 50 50 50 50 50 50 50 50 50 50 50 50 50
				50 50 50 50 50 50 50 50 50 50 50 50 50 50 50 50
				50 50 50 50 50 50 50 50 50 50 50 50 50 50 50 50
				50 50 50 50 50 50 50 50 50 50 50 50 50 50 50 50
				50 50 50 50 50 50 50 50 50 50 50 50 50 50 50 50
				50 50 50 50 50 50 50 50 50 50 50 50 50 50 50 50
				50 50 50 50 50 50 50 50 50 50 50 50 50 50 50 50
				50 50 50 50 50 50 50 50 50 50 50 50 50 50 50 50
				50 50 50 50 50 50 50 50 50 50 50 50 50 50 50 50
				50 50 50 50 50 50 50 50 50 50 50 50 50 50 50 50
				50 50 50 50 50 50 50 50 50 50 50 50 50 50 50 50
				50 50 50 50 50 50 50 50 50 50 50 50 50 50 50 50
				50 50 50 50 50 50 50 50 50 50 50 50 50 50 50 50
				50 50 50 50 50 50 50 50 50 50 50 50 50 50 50 50
				50 50 50 50 50 50 50 50 50 50 50 50 50 50 50 50
				50 50 50 50 50 50 50 50 50 50 50 50 50 50 50 50
				50 50 50 50 50 50 50 50 50 50 50 50 50 50 50 50
				50 50 50 50 50 50 50 50 50 50 50 50 50 50 50 50
				50 50 50 50 50 50 50 50 50 50 50 50 50 50 50 50
				>;

			PS_Config_Lmt_FW_Diff_N = <
				(-50) (-50) (-50) (-50) (-50) (-50) (-50) (-65535) (-65535) (-50) (-50) (-50) (-50) (-50) (-50) (-50)
				(-50) (-50) (-50) (-50) (-50) (-50) (-50) (-50) (-50) (-50) (-50) (-50) (-50) (-50) (-50) (-50)
				(-50) (-50) (-50) (-50) (-50) (-50) (-50) (-50) (-50) (-50) (-50) (-50) (-50) (-50) (-50) (-50)
				(-50) (-50) (-50) (-50) (-50) (-50) (-50) (-50) (-50) (-50) (-50) (-50) (-50) (-50) (-50) (-50)
				(-50) (-50) (-50) (-50) (-50) (-50) (-50) (-50) (-50) (-50) (-50) (-50) (-50) (-50) (-50) (-50)
				(-50) (-50) (-50) (-50) (-50) (-50) (-50) (-50) (-50) (-50) (-50) (-50) (-50) (-50) (-50) (-50)
				(-50) (-50) (-50) (-50) (-50) (-50) (-50) (-50) (-50) (-50) (-50) (-50) (-50) (-50) (-50) (-50)
				(-50) (-50) (-50) (-50) (-50) (-50) (-50) (-50) (-50) (-50) (-50) (-50) (-50) (-50) (-50) (-50)
				(-50) (-50) (-50) (-50) (-50) (-50) (-50) (-50) (-50) (-50) (-50) (-50) (-50) (-50) (-50) (-50)
				(-50) (-50) (-50) (-50) (-50) (-50) (-50) (-50) (-50) (-50) (-50) (-50) (-50) (-50) (-50) (-50)
				(-50) (-50) (-50) (-50) (-50) (-50) (-50) (-50) (-50) (-50) (-50) (-50) (-50) (-50) (-50) (-50)
				(-50) (-50) (-50) (-50) (-50) (-50) (-50) (-50) (-50) (-50) (-50) (-50) (-50) (-50) (-50) (-50)
				(-50) (-50) (-50) (-50) (-50) (-50) (-50) (-50) (-50) (-50) (-50) (-50) (-50) (-50) (-50) (-50)
				(-50) (-50) (-50) (-50) (-50) (-50) (-50) (-50) (-50) (-50) (-50) (-50) (-50) (-50) (-50) (-50)
				(-50) (-50) (-50) (-50) (-50) (-50) (-50) (-50) (-50) (-50) (-50) (-50) (-50) (-50) (-50) (-50)
				(-50) (-50) (-50) (-50) (-50) (-50) (-50) (-50) (-50) (-50) (-50) (-50) (-50) (-50) (-50) (-50)
				(-50) (-50) (-50) (-50) (-50) (-50) (-50) (-50) (-50) (-50) (-50) (-50) (-50) (-50) (-50) (-50)
				(-50) (-50) (-50) (-50) (-50) (-50) (-50) (-50) (-50) (-50) (-50) (-50) (-50) (-50) (-50) (-50)
				(-50) (-50) (-50) (-50) (-50) (-50) (-50) (-50) (-50) (-50) (-50) (-50) (-50) (-50) (-50) (-50)
				(-50) (-50) (-50) (-50) (-50) (-50) (-50) (-50) (-50) (-50) (-50) (-50) (-50) (-50) (-50) (-50)
				(-50) (-50) (-50) (-50) (-50) (-50) (-50) (-50) (-50) (-50) (-50) (-50) (-50) (-50) (-50) (-50)
				(-50) (-50) (-50) (-50) (-50) (-50) (-50) (-50) (-50) (-50) (-50) (-50) (-50) (-50) (-50) (-50)
				(-50) (-50) (-50) (-50) (-50) (-50) (-50) (-50) (-50) (-50) (-50) (-50) (-50) (-50) (-50) (-50)
				(-50) (-50) (-50) (-50) (-50) (-50) (-50) (-50) (-50) (-50) (-50) (-50) (-50) (-50) (-50) (-50)
				(-50) (-50) (-50) (-50) (-50) (-50) (-50) (-50) (-50) (-50) (-50) (-50) (-50) (-50) (-50) (-50)
				(-50) (-50) (-50) (-50) (-50) (-50) (-50) (-50) (-50) (-50) (-50) (-50) (-50) (-50) (-50) (-50)
				(-50) (-50) (-50) (-50) (-50) (-50) (-50) (-50) (-50) (-50) (-50) (-50) (-50) (-50) (-50) (-50)
				(-50) (-50) (-50) (-50) (-50) (-50) (-50) (-50) (-50) (-50) (-50) (-50) (-50) (-50) (-50) (-50)
				(-50) (-50) (-50) (-50) (-50) (-50) (-50) (-50) (-50) (-50) (-50) (-50) (-50) (-50) (-50) (-50)
				(-50) (-50) (-50) (-50) (-50) (-50) (-50) (-50) (-50) (-50) (-50) (-50) (-50) (-50) (-50) (-50)
				(-50) (-50) (-50) (-50) (-50) (-50) (-50) (-50) (-50) (-50) (-50) (-50) (-50) (-50) (-50) (-50)
				(-50) (-50) (-50) (-50) (-50) (-50) (-50) (-50) (-50) (-50) (-50) (-50) (-50) (-50) (-50) (-50)
				(-50) (-50) (-50) (-50) (-50) (-50) (-50) (-50) (-50) (-50) (-50) (-50) (-50) (-50) (-50) (-50)
				(-50) (-50) (-50) (-50) (-50) (-50) (-50) (-50) (-50) (-50) (-50) (-50) (-50) (-50) (-50) (-50)
				(-50) (-50) (-50) (-50) (-50) (-50) (-50) (-50) (-50) (-50) (-50) (-50) (-50) (-50) (-50) (-50)
				(-50) (-50) (-50) (-50) (-50) (-50) (-50) (-50) (-50) (-50) (-50) (-50) (-50) (-50) (-50) (-50)
				>;

			PS_Config_Diff_Test_Frame = <50>;

			Doze_X_Channel = <2>;

			PS_Config_Lmt_Doze_Rawdata_P = <
				370	370
				370	370
				370	370
				370	370
				370	370
				370	370
				370	370
				370	370
				370	370
				370	370
				370	370
				370	370
				370	370
				370	370
				370	370
				370	370
				370	370
				370	370
				370	370
				370	370
				370	370
				370	370
				370	370
				370	370
				370	370
				370	370
				370	370
				370	370
				370	370
				370	370
				370	370
				370	370
				370	370
				370	370
				370	370
				370	370
				>;

			PS_Config_Lmt_Doze_Rawdata_N = <
				30	30
				30	30
				30	30
				30	30
				30	30
				30	30
				30	30
				30	30
				30	30
				30	30
				30	30
				30	30
				30	30
				30	30
				30	30
				30	30
				30	30
				30	30
				30	30
				30	30
				30	30
				30	30
				30	30
				30	30
				30	30
				30	30
				30	30
				30	30
				30	30
				30	30
				30	30
				30	30
				30	30
				30	30
				30	30
				30	30
				>;

			PS_Config_Doze_Noise_Test_Frame = <50>;

			PS_Config_Lmt_Doze_Diff_P = <
				270	270
				270	270
				270	270
				270	270
				270	270
				270	270
				270	270
				270	270
				270	270
				270	270
				270	270
				270	270
				270	270
				270	270
				270	270
				270	270
				270	270
				270	270
				270	270
				270	270
				270	270
				270	270
				270	270
				270	270
				270	270
				270	270
				270	270
				270	270
				270	270
				270	270
				270	270
				270	270
				270	270
				270	270
				270	270
				270	270
				>;

			PS_Config_Lmt_Doze_Diff_N = <
				(-270)	(-270)
				(-270)	(-270)
				(-270)	(-270)
				(-270)	(-270)
				(-270)	(-270)
				(-270)	(-270)
				(-270)	(-270)
				(-270)	(-270)
				(-270)	(-270)
				(-270)	(-270)
				(-270)	(-270)
				(-270)	(-270)
				(-270)	(-270)
				(-270)	(-270)
				(-270)	(-270)
				(-270)	(-270)
				(-270)	(-270)
				(-270)	(-270)
				(-270)	(-270)
				(-270)	(-270)
				(-270)	(-270)
				(-270)	(-270)
				(-270)	(-270)
				(-270)	(-270)
				(-270)	(-270)
				(-270)	(-270)
				(-270)	(-270)
				(-270)	(-270)
				(-270)	(-270)
				(-270)	(-270)
				(-270)	(-270)
				(-270)	(-270)
				(-270)	(-270)
				(-270)	(-270)
				(-270)	(-270)
				(-270)	(-270)
				>;

			PS_Config_Lmt_LPWG_Rawdata_P = <
				1143 1121 1111 1106 1111 1103 1110 65535 65535 1113 1106 1127 1108 1108 1115 1121
				1114 1104 1108 1107 1118 1108 1113 1108 1124 1114 1103 1111 1107 1114 1110 1124
				1120 1114 1117 1111 1097 1104 1106 1110 1115 1114 1108 1110 1110 1115 1107 1124
				1124 1090 1101 1101 1086 1089 1086 1107 1111 1097 1122 1103 1110 1108 1113 1106
				1115 1110 1118 1114 1099 1104 1104 1104 1104 1103 1097 1090 1094 1103 1099 1108
				1107 1108 1099 1090 1113 1096 1101 1104 1104 1113 1103 1110 1113 1124 1115 1094
				1117 1117 1115 1129 1118 1127 1121 1129 1107 1113 1111 1111 1120 1113 1120 1108
				1135 1103 1106 1103 1104 1106 1100 1114 1114 1114 1118 1107 1113 1111 1115 1117
				1092 1078 1080 1078 1096 1079 1092 1086 1110 1108 1117 1115 1113 1111 1111 1104
				1104 1128 1134 1124 1131 1120 1132 1100 1148 1134 1132 1115 1113 1115 1121 1111
				1117 1108 1114 1115 1114 1110 1114 1113 1099 1096 1101 1093 1097 1096 1093 1117
				1090 1127 1129 1124 1111 1122 1117 1111 1113 1114 1110 1104 1106 1104 1113 1124
				1125 1131 1125 1127 1129 1124 1125 1117 1122 1118 1113 1110 1115 1108 1113 1117
				1120 1099 1110 1111 1110 1108 1114 1118 1100 1089 1094 1110 1111 1107 1089 1103
				1118 1120 1115 1110 1120 1111 1115 1115 1092 1087 1127 1094 1083 1097 1117 1100
				1113 1100 1115 1111 1106 1108 1107 1110 1104 1100 1099 1099 1099 1087 1097 1120
				1096 1097 1097 1100 1093 1103 1101 1115 1115 1122 1125 1121 1110 1100 1087 1139
				1100 1113 1114 1101 1103 1104 1103 1134 1110 1106 1099 1111 1111 1120 1111 1117
				1108 1107 1108 1108 1106 1110 1103 1103 1104 1101 1096 1092 1094 1090 1108 1111
				1121 1118 1118 1122 1120 1111 1117 1121 1101 1121 1117 1115 1127 1124 1113 1097
				1099 1127 1121 1120 1115 1117 1121 1111 1104 1118 1114 1115 1111 1113 1093 1118
				1115 1106 1110 1103 1108 1110 1113 1104 1117 1110 1106 1106 1113 1104 1097 1108
				1121 1111 1113 1114 1113 1120 1115 1114 1127 1129 1131 1118 1121 1113 1132 1115
				1117 1124 1124 1125 1113 1114 1110 1113 1099 1111 1101 1107 1103 1104 1104 1111
				1101 1108 1111 1103 1108 1100 1087 1093 1099 1101 1099 1097 1092 1097 1097 1136
				1110 1125 1124 1122 1093 1094 1106 1113 1087 1110 1111 1113 1093 1094 1104 1111
				1101 1113 1124 1121 1111 1108 1114 1122 1111 1122 1124 1114 1117 1103 1107 1118
				1114 1103 1124 1131 1134 1134 1135 1117 1121 1134 1127 1131 1120 1110 1108 1124
				1113 1110 1103 1100 1100 1100 1104 1107 1110 1117 1117 1117 1118 1111 1111 1110
				1122 1117 1122 1110 1103 1100 1099 1107 1107 1106 1106 1104 1111 1114 1118 1125
				1114 1094 1107 1104 1110 1100 1094 1092 1127 1108 1121 1122 1106 1103 1110 1117
				1131 1099 1117 1107 1111 1110 1108 1110 1117 1122 1115 1113 1128 1115 1115 1101
				1111 1117 1107 1101 1104 1085 1086 1092 1114 1121 1121 1122 1110 1124 1117 1117
				1125 1117 1115 1115 1107 1106 1106 1108 1111 1101 1104 1101 1104 1121 1118 1135
				1104 1142 1136 1132 1117 1120 1122 1125 1127 1118 1124 1122 1113 1096 1097 1096
				1106 1108 1100 1100 1104 1114 1114 1122 1129 1134 1122 1125 1108 1108 1104 1097
				>;

			PS_Config_Lmt_LPWG_Rawdata_N = <
				490 480 476 474 476 472 475 (-65535) (-65535) 477 474 483 475 475 478 480
				477 473 475 474 479 475 477 475 481 477 472 476 474 477 475 481
				480 477 478 476 470 473 474 475 478 477 475 475 475 478 474 481
				481 467 472 472 465 466 465 474 476 470 481 472 475 475 477 474
				478 475 479 477 471 473 473 473 473 472 470 467 469 472 471 475
				474 475 471 467 477 469 472 473 473 477 472 475 477 481 478 469
				478 478 478 484 479 483 480 484 474 477 476 476 480 477 480 475
				486 472 474 472 473 474 471 477 477 477 479 474 477 476 478 478
				468 462 463 462 469 462 468 465 475 475 478 478 477 476 476 473
				473 483 486 481 484 480 485 471 492 486 485 478 477 478 480 476
				478 475 477 478 477 475 477 477 471 469 472 468 470 469 468 478
				467 483 484 481 476 481 478 476 477 477 475 473 474 473 477 481
				482 484 482 483 484 481 482 478 481 479 477 475 478 475 477 478
				480 471 475 476 475 475 477 479 471 466 469 475 476 474 466 472
				479 480 478 475 480 476 478 478 468 466 483 469 464 470 478 471
				477 471 478 476 474 475 474 475 473 471 471 471 471 466 470 480
				469 470 470 471 468 472 472 478 478 481 482 480 475 471 466 488
				471 477 477 472 472 473 472 486 475 474 471 476 476 480 476 478
				475 474 475 475 474 475 472 472 473 472 469 468 469 467 475 476
				480 479 479 481 480 476 478 480 472 480 478 478 483 481 477 470
				471 483 480 480 478 478 480 476 473 479 477 478 476 477 468 479
				478 474 475 472 475 475 477 473 478 475 474 474 477 473 470 475
				480 476 477 477 477 480 478 477 483 484 484 479 480 477 485 478
				478 481 481 482 477 477 475 477 471 476 472 474 472 473 473 476
				472 475 476 472 475 471 466 468 471 472 471 470 468 470 470 487
				475 482 481 481 468 469 474 477 466 475 476 477 468 469 473 476
				472 477 481 480 476 475 477 481 476 481 481 477 478 472 474 479
				477 472 481 484 486 486 486 478 480 486 483 484 480 475 475 481
				477 475 472 471 471 471 473 474 475 478 478 478 479 476 476 475
				481 478 481 475 472 471 471 474 474 474 474 473 476 477 479 482
				477 469 474 473 475 471 469 468 483 475 480 481 474 472 475 478
				484 471 478 474 476 475 475 475 478 481 478 477 483 478 478 472
				476 478 474 472 473 465 465 468 477 480 480 481 475 481 478 478
				482 478 478 478 474 474 474 475 476 472 473 472 473 480 479 486
				473 489 487 485 478 480 481 482 483 479 481 481 477 469 470 469
				474 475 471 471 473 477 477 481 484 486 481 482 475 475 473 470
				>;

			PS_Config_Lmt_LPWG_Diff_P = <
				60 60 60 60 60 60 60 65535 65535 60 60 60 60 60 60 60
				60 60 60 60 60 60 60 60 60 60 60 60 60 60 60 60
				60 60 60 60 60 60 60 60 60 60 60 60 60 60 60 60
				60 60 60 60 60 60 60 60 60 60 60 60 60 60 60 60
				60 60 60 60 60 60 60 60 60 60 60 60 60 60 60 60
				60 60 60 60 60 60 60 60 60 60 60 60 60 60 60 60
				60 60 60 60 60 60 60 60 60 60 60 60 60 60 60 60
				60 60 60 60 60 60 60 60 60 60 60 60 60 60 60 60
				60 60 60 60 60 60 60 60 60 60 60 60 60 60 60 60
				60 60 60 60 60 60 60 60 60 60 60 60 60 60 60 60
				60 60 60 60 60 60 60 60 60 60 60 60 60 60 60 60
				60 60 60 60 60 60 60 60 60 60 60 60 60 60 60 60
				60 60 60 60 60 60 60 60 60 60 60 60 60 60 60 60
				60 60 60 60 60 60 60 60 60 60 60 60 60 60 60 60
				60 60 60 60 60 60 60 60 60 60 60 60 60 60 60 60
				60 60 60 60 60 60 60 60 60 60 60 60 60 60 60 60
				60 60 60 60 60 60 60 60 60 60 60 60 60 60 60 60
				60 60 60 60 60 60 60 60 60 60 60 60 60 60 60 60
				60 60 60 60 60 60 60 60 60 60 60 60 60 60 60 60
				60 60 60 60 60 60 60 60 60 60 60 60 60 60 60 60
				60 60 60 60 60 60 60 60 60 60 60 60 60 60 60 60
				60 60 60 60 60 60 60 60 60 60 60 60 60 60 60 60
				60 60 60 60 60 60 60 60 60 60 60 60 60 60 60 60
				60 60 60 60 60 60 60 60 60 60 60 60 60 60 60 60
				60 60 60 60 60 60 60 60 60 60 60 60 60 60 60 60
				60 60 60 60 60 60 60 60 60 60 60 60 60 60 60 60
				60 60 60 60 60 60 60 60 60 60 60 60 60 60 60 60
				60 60 60 60 60 60 60 60 60 60 60 60 60 60 60 60
				60 60 60 60 60 60 60 60 60 60 60 60 60 60 60 60
				60 60 60 60 60 60 60 60 60 60 60 60 60 60 60 60
				60 60 60 60 60 60 60 60 60 60 60 60 60 60 60 60
				60 60 60 60 60 60 60 60 60 60 60 60 60 60 60 60
				60 60 60 60 60 60 60 60 60 60 60 60 60 60 60 60
				60 60 60 60 60 60 60 60 60 60 60 60 60 60 60 60
				60 60 60 60 60 60 60 60 60 60 60 60 60 60 60 60
				60 60 60 60 60 60 60 60 60 60 60 60 60 60 60 60
				>;

			PS_Config_Lmt_LPWG_Diff_N = <
				(-60) (-60) (-60) (-60) (-60) (-60) (-60) (-65535) (-65535) (-60) (-60) (-60) (-60) (-60) (-60) (-60)
				(-60) (-60) (-60) (-60) (-60) (-60) (-60) (-60) (-60) (-60) (-60) (-60) (-60) (-60) (-60) (-60)
				(-60) (-60) (-60) (-60) (-60) (-60) (-60) (-60) (-60) (-60) (-60) (-60) (-60) (-60) (-60) (-60)
				(-60) (-60) (-60) (-60) (-60) (-60) (-60) (-60) (-60) (-60) (-60) (-60) (-60) (-60) (-60) (-60)
				(-60) (-60) (-60) (-60) (-60) (-60) (-60) (-60) (-60) (-60) (-60) (-60) (-60) (-60) (-60) (-60)
				(-60) (-60) (-60) (-60) (-60) (-60) (-60) (-60) (-60) (-60) (-60) (-60) (-60) (-60) (-60) (-60)
				(-60) (-60) (-60) (-60) (-60) (-60) (-60) (-60) (-60) (-60) (-60) (-60) (-60) (-60) (-60) (-60)
				(-60) (-60) (-60) (-60) (-60) (-60) (-60) (-60) (-60) (-60) (-60) (-60) (-60) (-60) (-60) (-60)
				(-60) (-60) (-60) (-60) (-60) (-60) (-60) (-60) (-60) (-60) (-60) (-60) (-60) (-60) (-60) (-60)
				(-60) (-60) (-60) (-60) (-60) (-60) (-60) (-60) (-60) (-60) (-60) (-60) (-60) (-60) (-60) (-60)
				(-60) (-60) (-60) (-60) (-60) (-60) (-60) (-60) (-60) (-60) (-60) (-60) (-60) (-60) (-60) (-60)
				(-60) (-60) (-60) (-60) (-60) (-60) (-60) (-60) (-60) (-60) (-60) (-60) (-60) (-60) (-60) (-60)
				(-60) (-60) (-60) (-60) (-60) (-60) (-60) (-60) (-60) (-60) (-60) (-60) (-60) (-60) (-60) (-60)
				(-60) (-60) (-60) (-60) (-60) (-60) (-60) (-60) (-60) (-60) (-60) (-60) (-60) (-60) (-60) (-60)
				(-60) (-60) (-60) (-60) (-60) (-60) (-60) (-60) (-60) (-60) (-60) (-60) (-60) (-60) (-60) (-60)
				(-60) (-60) (-60) (-60) (-60) (-60) (-60) (-60) (-60) (-60) (-60) (-60) (-60) (-60) (-60) (-60)
				(-60) (-60) (-60) (-60) (-60) (-60) (-60) (-60) (-60) (-60) (-60) (-60) (-60) (-60) (-60) (-60)
				(-60) (-60) (-60) (-60) (-60) (-60) (-60) (-60) (-60) (-60) (-60) (-60) (-60) (-60) (-60) (-60)
				(-60) (-60) (-60) (-60) (-60) (-60) (-60) (-60) (-60) (-60) (-60) (-60) (-60) (-60) (-60) (-60)
				(-60) (-60) (-60) (-60) (-60) (-60) (-60) (-60) (-60) (-60) (-60) (-60) (-60) (-60) (-60) (-60)
				(-60) (-60) (-60) (-60) (-60) (-60) (-60) (-60) (-60) (-60) (-60) (-60) (-60) (-60) (-60) (-60)
				(-60) (-60) (-60) (-60) (-60) (-60) (-60) (-60) (-60) (-60) (-60) (-60) (-60) (-60) (-60) (-60)
				(-60) (-60) (-60) (-60) (-60) (-60) (-60) (-60) (-60) (-60) (-60) (-60) (-60) (-60) (-60) (-60)
				(-60) (-60) (-60) (-60) (-60) (-60) (-60) (-60) (-60) (-60) (-60) (-60) (-60) (-60) (-60) (-60)
				(-60) (-60) (-60) (-60) (-60) (-60) (-60) (-60) (-60) (-60) (-60) (-60) (-60) (-60) (-60) (-60)
				(-60) (-60) (-60) (-60) (-60) (-60) (-60) (-60) (-60) (-60) (-60) (-60) (-60) (-60) (-60) (-60)
				(-60) (-60) (-60) (-60) (-60) (-60) (-60) (-60) (-60) (-60) (-60) (-60) (-60) (-60) (-60) (-60)
				(-60) (-60) (-60) (-60) (-60) (-60) (-60) (-60) (-60) (-60) (-60) (-60) (-60) (-60) (-60) (-60)
				(-60) (-60) (-60) (-60) (-60) (-60) (-60) (-60) (-60) (-60) (-60) (-60) (-60) (-60) (-60) (-60)
				(-60) (-60) (-60) (-60) (-60) (-60) (-60) (-60) (-60) (-60) (-60) (-60) (-60) (-60) (-60) (-60)
				(-60) (-60) (-60) (-60) (-60) (-60) (-60) (-60) (-60) (-60) (-60) (-60) (-60) (-60) (-60) (-60)
				(-60) (-60) (-60) (-60) (-60) (-60) (-60) (-60) (-60) (-60) (-60) (-60) (-60) (-60) (-60) (-60)
				(-60) (-60) (-60) (-60) (-60) (-60) (-60) (-60) (-60) (-60) (-60) (-60) (-60) (-60) (-60) (-60)
				(-60) (-60) (-60) (-60) (-60) (-60) (-60) (-60) (-60) (-60) (-60) (-60) (-60) (-60) (-60) (-60)
				(-60) (-60) (-60) (-60) (-60) (-60) (-60) (-60) (-60) (-60) (-60) (-60) (-60) (-60) (-60) (-60)
				(-60) (-60) (-60) (-60) (-60) (-60) (-60) (-60) (-60) (-60) (-60) (-60) (-60) (-60) (-60) (-60)
				>;

			FDM_X_Channel = <2>;

			PS_Config_Lmt_FDM_Rawdata_P = <
				370	370
				370	370
				370	370
				370	370
				370	370
				370	370
				370	370
				370	370
				370	370
				370	370
				370	370
				370	370
				370	370
				370	370
				370	370
				370	370
				370	370
				370	370
				370	370
				370	370
				370	370
				370	370
				370	370
				370	370
				370	370
				370	370
				370	370
				370	370
				370	370
				370	370
				370	370
				370	370
				370	370
				370	370
				370	370
				370	370
				>;

			PS_Config_Lmt_FDM_Rawdata_N = <
				30	30
				30	30
				30	30
				30	30
				30	30
				30	30
				30	30
				30	30
				30	30
				30	30
				30	30
				30	30
				30	30
				30	30
				30	30
				30	30
				30	30
				30	30
				30	30
				30	30
				30	30
				30	30
				30	30
				30	30
				30	30
				30	30
				30	30
				30	30
				30	30
				30	30
				30	30
				30	30
				30	30
				30	30
				30	30
				30	30
				>;

			PS_Config_FDM_Noise_Test_Frame = <50>;

			PS_Config_Lmt_FDM_Diff_P = <
				270	270
				270	270
				270	270
				270	270
				270	270
				270	270
				270	270
				270	270
				270	270
				270	270
				270	270
				270	270
				270	270
				270	270
				270	270
				270	270
				270	270
				270	270
				270	270
				270	270
				270	270
				270	270
				270	270
				270	270
				270	270
				270	270
				270	270
				270	270
				270	270
				270	270
				270	270
				270	270
				270	270
				270	270
				270	270
				270	270
				>;

			PS_Config_Lmt_FDM_Diff_N = <
				(-270)	(-270)
				(-270)	(-270)
				(-270)	(-270)
				(-270)	(-270)
				(-270)	(-270)
				(-270)	(-270)
				(-270)	(-270)
				(-270)	(-270)
				(-270)	(-270)
				(-270)	(-270)
				(-270)	(-270)
				(-270)	(-270)
				(-270)	(-270)
				(-270)	(-270)
				(-270)	(-270)
				(-270)	(-270)
				(-270)	(-270)
				(-270)	(-270)
				(-270)	(-270)
				(-270)	(-270)
				(-270)	(-270)
				(-270)	(-270)
				(-270)	(-270)
				(-270)	(-270)
				(-270)	(-270)
				(-270)	(-270)
				(-270)	(-270)
				(-270)	(-270)
				(-270)	(-270)
				(-270)	(-270)
				(-270)	(-270)
				(-270)	(-270)
				(-270)	(-270)
				(-270)	(-270)
				(-270)	(-270)
				(-270)	(-270)
				>;

			PS_Config_Lmt_FW_DigiDiff_P = <
				60 60 60 60 60 60 60 65535 65535 60 60 60 60 60 60 60
				60 60 60 60 60 60 60 60 60 60 60 60 60 60 60 60
				60 60 60 60 60 60 60 60 60 60 60 60 60 60 60 60
				60 60 60 60 60 60 60 60 60 60 60 60 60 60 60 60
				60 60 60 60 60 60 60 60 60 60 60 60 60 60 60 60
				60 60 60 60 60 60 60 60 60 60 60 60 60 60 60 60
				60 60 60 60 60 60 60 60 60 60 60 60 60 60 60 60
				60 60 60 60 60 60 60 60 60 60 60 60 60 60 60 60
				60 60 60 60 60 60 60 60 60 60 60 60 60 60 60 60
				60 60 60 60 60 60 60 60 60 60 60 60 60 60 60 60
				60 60 60 60 60 60 60 60 60 60 60 60 60 60 60 60
				60 60 60 60 60 60 60 60 60 60 60 60 60 60 60 60
				60 60 60 60 60 60 60 60 60 60 60 60 60 60 60 60
				60 60 60 60 60 60 60 60 60 60 60 60 60 60 60 60
				60 60 60 60 60 60 60 60 60 60 60 60 60 60 60 60
				60 60 60 60 60 60 60 60 60 60 60 60 60 60 60 60
				60 60 60 60 60 60 60 60 60 60 60 60 60 60 60 60
				60 60 60 60 60 60 60 60 60 60 60 60 60 60 60 60
				60 60 60 60 60 60 60 60 60 60 60 60 60 60 60 60
				60 60 60 60 60 60 60 60 60 60 60 60 60 60 60 60
				60 60 60 60 60 60 60 60 60 60 60 60 60 60 60 60
				60 60 60 60 60 60 60 60 60 60 60 60 60 60 60 60
				60 60 60 60 60 60 60 60 60 60 60 60 60 60 60 60
				60 60 60 60 60 60 60 60 60 60 60 60 60 60 60 60
				60 60 60 60 60 60 60 60 60 60 60 60 60 60 60 60
				60 60 60 60 60 60 60 60 60 60 60 60 60 60 60 60
				60 60 60 60 60 60 60 60 60 60 60 60 60 60 60 60
				60 60 60 60 60 60 60 60 60 60 60 60 60 60 60 60
				60 60 60 60 60 60 60 60 60 60 60 60 60 60 60 60
				60 60 60 60 60 60 60 60 60 60 60 60 60 60 60 60
				60 60 60 60 60 60 60 60 60 60 60 60 60 60 60 60
				60 60 60 60 60 60 60 60 60 60 60 60 60 60 60 60
				60 60 60 60 60 60 60 60 60 60 60 60 60 60 60 60
				60 60 60 60 60 60 60 60 60 60 60 60 60 60 60 60
				60 60 60 60 60 60 60 60 60 60 60 60 60 60 60 60
				60 60 60 60 60 60 60 60 60 60 60 60 60 60 60 60
				>;

			PS_Config_Lmt_FW_DigiDiff_N = <
				(-60) (-60) (-60) (-60) (-60) (-60) (-60) (-65535) (-65535) (-60) (-60) (-60) (-60) (-60) (-60) (-60)
				(-60) (-60) (-60) (-60) (-60) (-60) (-60) (-60) (-60) (-60) (-60) (-60) (-60) (-60) (-60) (-60)
				(-60) (-60) (-60) (-60) (-60) (-60) (-60) (-60) (-60) (-60) (-60) (-60) (-60) (-60) (-60) (-60)
				(-60) (-60) (-60) (-60) (-60) (-60) (-60) (-60) (-60) (-60) (-60) (-60) (-60) (-60) (-60) (-60)
				(-60) (-60) (-60) (-60) (-60) (-60) (-60) (-60) (-60) (-60) (-60) (-60) (-60) (-60) (-60) (-60)
				(-60) (-60) (-60) (-60) (-60) (-60) (-60) (-60) (-60) (-60) (-60) (-60) (-60) (-60) (-60) (-60)
				(-60) (-60) (-60) (-60) (-60) (-60) (-60) (-60) (-60) (-60) (-60) (-60) (-60) (-60) (-60) (-60)
				(-60) (-60) (-60) (-60) (-60) (-60) (-60) (-60) (-60) (-60) (-60) (-60) (-60) (-60) (-60) (-60)
				(-60) (-60) (-60) (-60) (-60) (-60) (-60) (-60) (-60) (-60) (-60) (-60) (-60) (-60) (-60) (-60)
				(-60) (-60) (-60) (-60) (-60) (-60) (-60) (-60) (-60) (-60) (-60) (-60) (-60) (-60) (-60) (-60)
				(-60) (-60) (-60) (-60) (-60) (-60) (-60) (-60) (-60) (-60) (-60) (-60) (-60) (-60) (-60) (-60)
				(-60) (-60) (-60) (-60) (-60) (-60) (-60) (-60) (-60) (-60) (-60) (-60) (-60) (-60) (-60) (-60)
				(-60) (-60) (-60) (-60) (-60) (-60) (-60) (-60) (-60) (-60) (-60) (-60) (-60) (-60) (-60) (-60)
				(-60) (-60) (-60) (-60) (-60) (-60) (-60) (-60) (-60) (-60) (-60) (-60) (-60) (-60) (-60) (-60)
				(-60) (-60) (-60) (-60) (-60) (-60) (-60) (-60) (-60) (-60) (-60) (-60) (-60) (-60) (-60) (-60)
				(-60) (-60) (-60) (-60) (-60) (-60) (-60) (-60) (-60) (-60) (-60) (-60) (-60) (-60) (-60) (-60)
				(-60) (-60) (-60) (-60) (-60) (-60) (-60) (-60) (-60) (-60) (-60) (-60) (-60) (-60) (-60) (-60)
				(-60) (-60) (-60) (-60) (-60) (-60) (-60) (-60) (-60) (-60) (-60) (-60) (-60) (-60) (-60) (-60)
				(-60) (-60) (-60) (-60) (-60) (-60) (-60) (-60) (-60) (-60) (-60) (-60) (-60) (-60) (-60) (-60)
				(-60) (-60) (-60) (-60) (-60) (-60) (-60) (-60) (-60) (-60) (-60) (-60) (-60) (-60) (-60) (-60)
				(-60) (-60) (-60) (-60) (-60) (-60) (-60) (-60) (-60) (-60) (-60) (-60) (-60) (-60) (-60) (-60)
				(-60) (-60) (-60) (-60) (-60) (-60) (-60) (-60) (-60) (-60) (-60) (-60) (-60) (-60) (-60) (-60)
				(-60) (-60) (-60) (-60) (-60) (-60) (-60) (-60) (-60) (-60) (-60) (-60) (-60) (-60) (-60) (-60)
				(-60) (-60) (-60) (-60) (-60) (-60) (-60) (-60) (-60) (-60) (-60) (-60) (-60) (-60) (-60) (-60)
				(-60) (-60) (-60) (-60) (-60) (-60) (-60) (-60) (-60) (-60) (-60) (-60) (-60) (-60) (-60) (-60)
				(-60) (-60) (-60) (-60) (-60) (-60) (-60) (-60) (-60) (-60) (-60) (-60) (-60) (-60) (-60) (-60)
				(-60) (-60) (-60) (-60) (-60) (-60) (-60) (-60) (-60) (-60) (-60) (-60) (-60) (-60) (-60) (-60)
				(-60) (-60) (-60) (-60) (-60) (-60) (-60) (-60) (-60) (-60) (-60) (-60) (-60) (-60) (-60) (-60)
				(-60) (-60) (-60) (-60) (-60) (-60) (-60) (-60) (-60) (-60) (-60) (-60) (-60) (-60) (-60) (-60)
				(-60) (-60) (-60) (-60) (-60) (-60) (-60) (-60) (-60) (-60) (-60) (-60) (-60) (-60) (-60) (-60)
				(-60) (-60) (-60) (-60) (-60) (-60) (-60) (-60) (-60) (-60) (-60) (-60) (-60) (-60) (-60) (-60)
				(-60) (-60) (-60) (-60) (-60) (-60) (-60) (-60) (-60) (-60) (-60) (-60) (-60) (-60) (-60) (-60)
				(-60) (-60) (-60) (-60) (-60) (-60) (-60) (-60) (-60) (-60) (-60) (-60) (-60) (-60) (-60) (-60)
				(-60) (-60) (-60) (-60) (-60) (-60) (-60) (-60) (-60) (-60) (-60) (-60) (-60) (-60) (-60) (-60)
				(-60) (-60) (-60) (-60) (-60) (-60) (-60) (-60) (-60) (-60) (-60) (-60) (-60) (-60) (-60) (-60)
				(-60) (-60) (-60) (-60) (-60) (-60) (-60) (-60) (-60) (-60) (-60) (-60) (-60) (-60) (-60) (-60)
				>;
		};

		/* MP Criteria For CSOT */
		novatek-mp-criteria-csot@1 {
			#address-cells = <1>;
			#size-cells = <0>;
			compatible = "novatek-mp-criteria-csot";

			/* MP Config */
			IC_X_CFG_SIZE = <16>;
			IC_Y_CFG_SIZE = <36>;
			IC_KEY_CFG_SIZE = <4>;
			X_Channel = <16>;
			Y_Channel = <36>;
			AIN_X = <0 1 2 3 4 5 6 7 8 9 10 11 12 13 14 15>;
			AIN_Y = <0 1 2 3 4 5 6 7 8 9 10 11 12 13 14 15 16 17 18 19 20 21 22 23 24 25 26 27 28 29 30 31 32 33 34 35>;
			AIN_KEY = <0 1 2 0xFF>;

			/* MP Criteria */
			PS_Config_Lmt_Short_Rawdata_P = <
				14008 14008 14008 14008 14008 14008 14008 14008 14008 14008 14008 14008 14008 14008 14008 14008
				14008 14008 14008 14008 14008 14008 14008 14008 14008 14008 14008 14008 14008 14008 14008 14008
				14008 14008 14008 14008 14008 14008 14008 14008 14008 14008 14008 14008 14008 14008 14008 14008
				14008 14008 14008 14008 14008 14008 14008 14008 14008 14008 14008 14008 14008 14008 14008 14008
				14008 14008 14008 14008 14008 14008 14008 14008 14008 14008 14008 14008 14008 14008 14008 14008
				14008 14008 14008 14008 14008 14008 14008 14008 14008 14008 14008 14008 14008 14008 14008 14008
				14008 14008 14008 14008 14008 14008 14008 14008 14008 14008 14008 14008 14008 14008 14008 14008
				14008 14008 14008 14008 14008 14008 14008 14008 14008 14008 14008 14008 14008 14008 14008 14008
				14008 14008 14008 14008 14008 14008 14008 14008 14008 14008 14008 14008 14008 14008 14008 14008
				14008 14008 14008 14008 14008 14008 14008 14008 14008 14008 14008 14008 14008 14008 14008 14008
				14008 14008 14008 14008 14008 14008 14008 14008 14008 14008 14008 14008 14008 14008 14008 14008
				14008 14008 14008 14008 14008 14008 14008 14008 14008 14008 14008 14008 14008 14008 14008 14008
				14008 14008 14008 14008 14008 14008 14008 14008 14008 14008 14008 14008 14008 14008 14008 14008
				14008 14008 14008 14008 14008 14008 14008 14008 14008 14008 14008 14008 14008 14008 14008 14008
				14008 14008 14008 14008 14008 14008 14008 14008 14008 14008 14008 14008 14008 14008 14008 14008
				14008 14008 14008 14008 14008 14008 14008 14008 14008 14008 14008 14008 14008 14008 14008 14008
				14008 14008 14008 14008 14008 14008 14008 14008 14008 14008 14008 14008 14008 14008 14008 14008
				14008 14008 14008 14008 14008 14008 14008 14008 14008 14008 14008 14008 14008 14008 14008 14008
				14008 14008 14008 14008 14008 14008 14008 14008 14008 14008 14008 14008 14008 14008 14008 14008
				14008 14008 14008 14008 14008 14008 14008 14008 14008 14008 14008 14008 14008 14008 14008 14008
				14008 14008 14008 14008 14008 14008 14008 14008 14008 14008 14008 14008 14008 14008 14008 14008
				14008 14008 14008 14008 14008 14008 14008 14008 14008 14008 14008 14008 14008 14008 14008 14008
				14008 14008 14008 14008 14008 14008 14008 14008 14008 14008 14008 14008 14008 14008 14008 14008
				14008 14008 14008 14008 14008 14008 14008 14008 14008 14008 14008 14008 14008 14008 14008 14008
				14008 14008 14008 14008 14008 14008 14008 14008 14008 14008 14008 14008 14008 14008 14008 14008
				14008 14008 14008 14008 14008 14008 14008 14008 14008 14008 14008 14008 14008 14008 14008 14008
				14008 14008 14008 14008 14008 14008 14008 14008 14008 14008 14008 14008 14008 14008 14008 14008
				14008 14008 14008 14008 14008 14008 14008 14008 14008 14008 14008 14008 14008 14008 14008 14008
				14008 14008 14008 14008 14008 14008 14008 14008 14008 14008 14008 14008 14008 14008 14008 14008
				14008 14008 14008 14008 14008 14008 14008 14008 14008 14008 14008 14008 14008 14008 14008 14008
				14008 14008 14008 14008 14008 14008 14008 14008 14008 14008 14008 14008 14008 14008 14008 14008
				14008 14008 14008 14008 14008 14008 14008 14008 14008 14008 14008 14008 14008 14008 14008 14008
				14008 14008 14008 14008 14008 14008 14008 14008 14008 14008 14008 14008 14008 14008 14008 14008
				14008 14008 14008 14008 14008 14008 14008 14008 14008 14008 14008 14008 14008 14008 14008 14008
				14008 14008 14008 14008 14008 14008 14008 14008 14008 14008 14008 14008 14008 14008 14008 14008
				14008 14008 14008 14008 14008 14008 14008 14008 14008 14008 14008 14008 14008 14008 14008 14008
				>;

			PS_Config_Lmt_Short_Rawdata_N = <
				10000 10000 10000 10000 10000 10000 10000 10000 10000 10000 10000 10000 10000 10000 10000 10000
				10000 10000 10000 10000 10000 10000 10000 10000 10000 10000 10000 10000 10000 10000 10000 10000
				10000 10000 10000 10000 10000 10000 10000 10000 10000 10000 10000 10000 10000 10000 10000 10000
				10000 10000 10000 10000 10000 10000 10000 10000 10000 10000 10000 10000 10000 10000 10000 10000
				10000 10000 10000 10000 10000 10000 10000 10000 10000 10000 10000 10000 10000 10000 10000 10000
				10000 10000 10000 10000 10000 10000 10000 10000 10000 10000 10000 10000 10000 10000 10000 10000
				10000 10000 10000 10000 10000 10000 10000 10000 10000 10000 10000 10000 10000 10000 10000 10000
				10000 10000 10000 10000 10000 10000 10000 10000 10000 10000 10000 10000 10000 10000 10000 10000
				10000 10000 10000 10000 10000 10000 10000 10000 10000 10000 10000 10000 10000 10000 10000 10000
				10000 10000 10000 10000 10000 10000 10000 10000 10000 10000 10000 10000 10000 10000 10000 10000
				10000 10000 10000 10000 10000 10000 10000 10000 10000 10000 10000 10000 10000 10000 10000 10000
				10000 10000 10000 10000 10000 10000 10000 10000 10000 10000 10000 10000 10000 10000 10000 10000
				10000 10000 10000 10000 10000 10000 10000 10000 10000 10000 10000 10000 10000 10000 10000 10000
				10000 10000 10000 10000 10000 10000 10000 10000 10000 10000 10000 10000 10000 10000 10000 10000
				10000 10000 10000 10000 10000 10000 10000 10000 10000 10000 10000 10000 10000 10000 10000 10000
				10000 10000 10000 10000 10000 10000 10000 10000 10000 10000 10000 10000 10000 10000 10000 10000
				10000 10000 10000 10000 10000 10000 10000 10000 10000 10000 10000 10000 10000 10000 10000 10000
				10000 10000 10000 10000 10000 10000 10000 10000 10000 10000 10000 10000 10000 10000 10000 10000
				10000 10000 10000 10000 10000 10000 10000 10000 10000 10000 10000 10000 10000 10000 10000 10000
				10000 10000 10000 10000 10000 10000 10000 10000 10000 10000 10000 10000 10000 10000 10000 10000
				10000 10000 10000 10000 10000 10000 10000 10000 10000 10000 10000 10000 10000 10000 10000 10000
				10000 10000 10000 10000 10000 10000 10000 10000 10000 10000 10000 10000 10000 10000 10000 10000
				10000 10000 10000 10000 10000 10000 10000 10000 10000 10000 10000 10000 10000 10000 10000 10000
				10000 10000 10000 10000 10000 10000 10000 10000 10000 10000 10000 10000 10000 10000 10000 10000
				10000 10000 10000 10000 10000 10000 10000 10000 10000 10000 10000 10000 10000 10000 10000 10000
				10000 10000 10000 10000 10000 10000 10000 10000 10000 10000 10000 10000 10000 10000 10000 10000
				10000 10000 10000 10000 10000 10000 10000 10000 10000 10000 10000 10000 10000 10000 10000 10000
				10000 10000 10000 10000 10000 10000 10000 10000 10000 10000 10000 10000 10000 10000 10000 10000
				10000 10000 10000 10000 10000 10000 10000 10000 10000 10000 10000 10000 10000 10000 10000 10000
				10000 10000 10000 10000 10000 10000 10000 10000 10000 10000 10000 10000 10000 10000 10000 10000
				10000 10000 10000 10000 10000 10000 10000 10000 10000 10000 10000 10000 10000 10000 10000 10000
				10000 10000 10000 10000 10000 10000 10000 10000 10000 10000 10000 10000 10000 10000 10000 10000
				10000 10000 10000 10000 10000 10000 10000 10000 10000 10000 10000 10000 10000 10000 10000 10000
				10000 10000 10000 10000 10000 10000 10000 10000 10000 10000 10000 10000 10000 10000 10000 10000
				10000 10000 10000 10000 10000 10000 10000 10000 10000 10000 10000 10000 10000 10000 10000 10000
				10000 10000 10000 10000 10000 10000 10000 10000 10000 10000 10000 10000 10000 10000 10000 10000
				>;

			PS_Config_Lmt_Open_Rawdata_P = <
				5120 5120 5120 5120 5120 5120 5120 5120 5120 5120 5120 5120 5120 5120 5120 5120
				5120 5120 5120 5120 5120 5120 5120 5120 5120 5120 5120 5120 5120 5120 5120 5120
				5120 5120 5120 5120 5120 5120 5120 5120 5120 5120 5120 5120 5120 5120 5120 5120
				5120 5120 5120 5120 5120 5120 5120 5120 5120 5120 5120 5120 5120 5120 5120 5120
				5120 5120 5120 5120 5120 5120 5120 5120 5120 5120 5120 5120 5120 5120 5120 5120
				5120 5120 5120 5120 5120 5120 5120 5120 5120 5120 5120 5120 5120 5120 5120 5120
				5120 5120 5120 5120 5120 5120 5120 5120 5120 5120 5120 5120 5120 5120 5120 5120
				5120 5120 5120 5120 5120 5120 5120 5120 5120 5120 5120 5120 5120 5120 5120 5120
				5120 5120 5120 5120 5120 5120 5120 5120 5120 5120 5120 5120 5120 5120 5120 5120
				5120 5120 5120 5120 5120 5120 5120 5120 5120 5120 5120 5120 5120 5120 5120 5120
				5120 5120 5120 5120 5120 5120 5120 5120 5120 5120 5120 5120 5120 5120 5120 5120
				5120 5120 5120 5120 5120 5120 5120 5120 5120 5120 5120 5120 5120 5120 5120 5120
				5120 5120 5120 5120 5120 5120 5120 5120 5120 5120 5120 5120 5120 5120 5120 5120
				5120 5120 5120 5120 5120 5120 5120 5120 5120 5120 5120 5120 5120 5120 5120 5120
				5120 5120 5120 5120 5120 5120 5120 5120 5120 5120 5120 5120 5120 5120 5120 5120
				5120 5120 5120 5120 5120 5120 5120 5120 5120 5120 5120 5120 5120 5120 5120 5120
				5120 5120 5120 5120 5120 5120 5120 5120 5120 5120 5120 5120 5120 5120 5120 5120
				5120 5120 5120 5120 5120 5120 5120 5120 5120 5120 5120 5120 5120 5120 5120 5120
				5120 5120 5120 5120 5120 5120 5120 5120 5120 5120 5120 5120 5120 5120 5120 5120
				5120 5120 5120 5120 5120 5120 5120 5120 5120 5120 5120 5120 5120 5120 5120 5120
				5120 5120 5120 5120 5120 5120 5120 5120 5120 5120 5120 5120 5120 5120 5120 5120
				5120 5120 5120 5120 5120 5120 5120 5120 5120 5120 5120 5120 5120 5120 5120 5120
				5120 5120 5120 5120 5120 5120 5120 5120 5120 5120 5120 5120 5120 5120 5120 5120
				5120 5120 5120 5120 5120 5120 5120 5120 5120 5120 5120 5120 5120 5120 5120 5120
				5120 5120 5120 5120 5120 5120 5120 5120 5120 5120 5120 5120 5120 5120 5120 5120
				5120 5120 5120 5120 5120 5120 5120 5120 5120 5120 5120 5120 5120 5120 5120 5120
				5120 5120 5120 5120 5120 5120 5120 5120 5120 5120 5120 5120 5120 5120 5120 5120
				5120 5120 5120 5120 5120 5120 5120 5120 5120 5120 5120 5120 5120 5120 5120 5120
				5120 5120 5120 5120 5120 5120 5120 5120 5120 5120 5120 5120 5120 5120 5120 5120
				5120 5120 5120 5120 5120 5120 5120 5120 5120 5120 5120 5120 5120 5120 5120 5120
				5120 5120 5120 5120 5120 5120 5120 5120 5120 5120 5120 5120 5120 5120 5120 5120
				5120 5120 5120 5120 5120 5120 5120 5120 5120 5120 5120 5120 5120 5120 5120 5120
				5120 5120 5120 5120 5120 5120 5120 5120 5120 5120 5120 5120 5120 5120 5120 5120
				5120 5120 5120 5120 5120 5120 5120 5120 5120 5120 5120 5120 5120 5120 5120 5120
				5120 5120 5120 5120 5120 5120 5120 5120 5120 5120 5120 5120 5120 5120 5120 5120
				5120 5120 5120 5120 5120 5120 5120 5120 5120 5120 5120 5120 5120 5120 5120 5120
				>;

			PS_Config_Lmt_Open_Rawdata_N = <
				(-511) (-511) (-511) (-511) (-511) (-511) (-511) (-511) (-511) (-511) (-511) (-511) (-511) (-511) (-511) (-511)
				(-511) (-511) (-511) (-511) (-511) (-511) (-511) (-511) (-511) (-511) (-511) (-511) (-511) (-511) (-511) (-511)
				(-511) (-511) (-511) (-511) (-511) (-511) (-511) (-511) (-511) (-511) (-511) (-511) (-511) (-511) (-511) (-511)
				(-511) (-511) (-511) (-511) (-511) (-511) (-511) (-511) (-511) (-511) (-511) (-511) (-511) (-511) (-511) (-511)
				(-511) (-511) (-511) (-511) (-511) (-511) (-511) (-511) (-511) (-511) (-511) (-511) (-511) (-511) (-511) (-511)
				(-511) (-511) (-511) (-511) (-511) (-511) (-511) (-511) (-511) (-511) (-511) (-511) (-511) (-511) (-511) (-511)
				(-511) (-511) (-511) (-511) (-511) (-511) (-511) (-511) (-511) (-511) (-511) (-511) (-511) (-511) (-511) (-511)
				(-511) (-511) (-511) (-511) (-511) (-511) (-511) (-511) (-511) (-511) (-511) (-511) (-511) (-511) (-511) (-511)
				(-511) (-511) (-511) (-511) (-511) (-511) (-511) (-511) (-511) (-511) (-511) (-511) (-511) (-511) (-511) (-511)
				(-511) (-511) (-511) (-511) (-511) (-511) (-511) (-511) (-511) (-511) (-511) (-511) (-511) (-511) (-511) (-511)
				(-511) (-511) (-511) (-511) (-511) (-511) (-511) (-511) (-511) (-511) (-511) (-511) (-511) (-511) (-511) (-511)
				(-511) (-511) (-511) (-511) (-511) (-511) (-511) (-511) (-511) (-511) (-511) (-511) (-511) (-511) (-511) (-511)
				(-511) (-511) (-511) (-511) (-511) (-511) (-511) (-511) (-511) (-511) (-511) (-511) (-511) (-511) (-511) (-511)
				(-511) (-511) (-511) (-511) (-511) (-511) (-511) (-511) (-511) (-511) (-511) (-511) (-511) (-511) (-511) (-511)
				(-511) (-511) (-511) (-511) (-511) (-511) (-511) (-511) (-511) (-511) (-511) (-511) (-511) (-511) (-511) (-511)
				(-511) (-511) (-511) (-511) (-511) (-511) (-511) (-511) (-511) (-511) (-511) (-511) (-511) (-511) (-511) (-511)
				(-511) (-511) (-511) (-511) (-511) (-511) (-511) (-511) (-511) (-511) (-511) (-511) (-511) (-511) (-511) (-511)
				(-511) (-511) (-511) (-511) (-511) (-511) (-511) (-511) (-511) (-511) (-511) (-511) (-511) (-511) (-511) (-511)
				(-511) (-511) (-511) (-511) (-511) (-511) (-511) (-511) (-511) (-511) (-511) (-511) (-511) (-511) (-511) (-511)
				(-511) (-511) (-511) (-511) (-511) (-511) (-511) (-511) (-511) (-511) (-511) (-511) (-511) (-511) (-511) (-511)
				(-511) (-511) (-511) (-511) (-511) (-511) (-511) (-511) (-511) (-511) (-511) (-511) (-511) (-511) (-511) (-511)
				(-511) (-511) (-511) (-511) (-511) (-511) (-511) (-511) (-511) (-511) (-511) (-511) (-511) (-511) (-511) (-511)
				(-511) (-511) (-511) (-511) (-511) (-511) (-511) (-511) (-511) (-511) (-511) (-511) (-511) (-511) (-511) (-511)
				(-511) (-511) (-511) (-511) (-511) (-511) (-511) (-511) (-511) (-511) (-511) (-511) (-511) (-511) (-511) (-511)
				(-511) (-511) (-511) (-511) (-511) (-511) (-511) (-511) (-511) (-511) (-511) (-511) (-511) (-511) (-511) (-511)
				(-511) (-511) (-511) (-511) (-511) (-511) (-511) (-511) (-511) (-511) (-511) (-511) (-511) (-511) (-511) (-511)
				(-511) (-511) (-511) (-511) (-511) (-511) (-511) (-511) (-511) (-511) (-511) (-511) (-511) (-511) (-511) (-511)
				(-511) (-511) (-511) (-511) (-511) (-511) (-511) (-511) (-511) (-511) (-511) (-511) (-511) (-511) (-511) (-511)
				(-511) (-511) (-511) (-511) (-511) (-511) (-511) (-511) (-511) (-511) (-511) (-511) (-511) (-511) (-511) (-511)
				(-511) (-511) (-511) (-511) (-511) (-511) (-511) (-511) (-511) (-511) (-511) (-511) (-511) (-511) (-511) (-511)
				(-511) (-511) (-511) (-511) (-511) (-511) (-511) (-511) (-511) (-511) (-511) (-511) (-511) (-511) (-511) (-511)
				(-511) (-511) (-511) (-511) (-511) (-511) (-511) (-511) (-511) (-511) (-511) (-511) (-511) (-511) (-511) (-511)
				(-511) (-511) (-511) (-511) (-511) (-511) (-511) (-511) (-511) (-511) (-511) (-511) (-511) (-511) (-511) (-511)
				(-511) (-511) (-511) (-511) (-511) (-511) (-511) (-511) (-511) (-511) (-511) (-511) (-511) (-511) (-511) (-511)
				(-511) (-511) (-511) (-511) (-511) (-511) (-511) (-511) (-511) (-511) (-511) (-511) (-511) (-511) (-511) (-511)
				(-511) (-511) (-511) (-511) (-511) (-511) (-511) (-511) (-511) (-511) (-511) (-511) (-511) (-511) (-511) (-511)
				>;

			PS_Config_Lmt_FW_Rawdata_P = <
				3840 3840 3840 3840 3840 3840 3840 3840 3840 3840 3840 3840 3840 3840 3840 3840
				3840 3840 3840 3840 3840 3840 3840 3840 3840 3840 3840 3840 3840 3840 3840 3840
				3840 3840 3840 3840 3840 3840 3840 3840 3840 3840 3840 3840 3840 3840 3840 3840
				3840 3840 3840 3840 3840 3840 3840 3840 3840 3840 3840 3840 3840 3840 3840 3840
				3840 3840 3840 3840 3840 3840 3840 3840 3840 3840 3840 3840 3840 3840 3840 3840
				3840 3840 3840 3840 3840 3840 3840 3840 3840 3840 3840 3840 3840 3840 3840 3840
				3840 3840 3840 3840 3840 3840 3840 3840 3840 3840 3840 3840 3840 3840 3840 3840
				3840 3840 3840 3840 3840 3840 3840 3840 3840 3840 3840 3840 3840 3840 3840 3840
				3840 3840 3840 3840 3840 3840 3840 3840 3840 3840 3840 3840 3840 3840 3840 3840
				3840 3840 3840 3840 3840 3840 3840 3840 3840 3840 3840 3840 3840 3840 3840 3840
				3840 3840 3840 3840 3840 3840 3840 3840 3840 3840 3840 3840 3840 3840 3840 3840
				3840 3840 3840 3840 3840 3840 3840 3840 3840 3840 3840 3840 3840 3840 3840 3840
				3840 3840 3840 3840 3840 3840 3840 3840 3840 3840 3840 3840 3840 3840 3840 3840
				3840 3840 3840 3840 3840 3840 3840 3840 3840 3840 3840 3840 3840 3840 3840 3840
				3840 3840 3840 3840 3840 3840 3840 3840 3840 3840 3840 3840 3840 3840 3840 3840
				3840 3840 3840 3840 3840 3840 3840 3840 3840 3840 3840 3840 3840 3840 3840 3840
				3840 3840 3840 3840 3840 3840 3840 3840 3840 3840 3840 3840 3840 3840 3840 3840
				3840 3840 3840 3840 3840 3840 3840 3840 3840 3840 3840 3840 3840 3840 3840 3840
				3840 3840 3840 3840 3840 3840 3840 3840 3840 3840 3840 3840 3840 3840 3840 3840
				3840 3840 3840 3840 3840 3840 3840 3840 3840 3840 3840 3840 3840 3840 3840 3840
				3840 3840 3840 3840 3840 3840 3840 3840 3840 3840 3840 3840 3840 3840 3840 3840
				3840 3840 3840 3840 3840 3840 3840 3840 3840 3840 3840 3840 3840 3840 3840 3840
				3840 3840 3840 3840 3840 3840 3840 3840 3840 3840 3840 3840 3840 3840 3840 3840
				3840 3840 3840 3840 3840 3840 3840 3840 3840 3840 3840 3840 3840 3840 3840 3840
				3840 3840 3840 3840 3840 3840 3840 3840 3840 3840 3840 3840 3840 3840 3840 3840
				3840 3840 3840 3840 3840 3840 3840 3840 3840 3840 3840 3840 3840 3840 3840 3840
				3840 3840 3840 3840 3840 3840 3840 3840 3840 3840 3840 3840 3840 3840 3840 3840
				3840 3840 3840 3840 3840 3840 3840 3840 3840 3840 3840 3840 3840 3840 3840 3840
				3840 3840 3840 3840 3840 3840 3840 3840 3840 3840 3840 3840 3840 3840 3840 3840
				3840 3840 3840 3840 3840 3840 3840 3840 3840 3840 3840 3840 3840 3840 3840 3840
				3840 3840 3840 3840 3840 3840 3840 3840 3840 3840 3840 3840 3840 3840 3840 3840
				3840 3840 3840 3840 3840 3840 3840 3840 3840 3840 3840 3840 3840 3840 3840 3840
				3840 3840 3840 3840 3840 3840 3840 3840 3840 3840 3840 3840 3840 3840 3840 3840
				3840 3840 3840 3840 3840 3840 3840 3840 3840 3840 3840 3840 3840 3840 3840 3840
				3840 3840 3840 3840 3840 3840 3840 3840 3840 3840 3840 3840 3840 3840 3840 3840
				3840 3840 3840 3840 3840 3840 3840 3840 3840 3840 3840 3840 3840 3840 3840 3840
				>;

			PS_Config_Lmt_FW_Rawdata_N = <
				240 240 240 240 240 240 240 240 240 240 240 240 240 240 240 240
				240 240 240 240 240 240 240 240 240 240 240 240 240 240 240 240
				240 240 240 240 240 240 240 240 240 240 240 240 240 240 240 240
				240 240 240 240 240 240 240 240 240 240 240 240 240 240 240 240
				240 240 240 240 240 240 240 240 240 240 240 240 240 240 240 240
				240 240 240 240 240 240 240 240 240 240 240 240 240 240 240 240
				240 240 240 240 240 240 240 240 240 240 240 240 240 240 240 240
				240 240 240 240 240 240 240 240 240 240 240 240 240 240 240 240
				240 240 240 240 240 240 240 240 240 240 240 240 240 240 240 240
				240 240 240 240 240 240 240 240 240 240 240 240 240 240 240 240
				240 240 240 240 240 240 240 240 240 240 240 240 240 240 240 240
				240 240 240 240 240 240 240 240 240 240 240 240 240 240 240 240
				240 240 240 240 240 240 240 240 240 240 240 240 240 240 240 240
				240 240 240 240 240 240 240 240 240 240 240 240 240 240 240 240
				240 240 240 240 240 240 240 240 240 240 240 240 240 240 240 240
				240 240 240 240 240 240 240 240 240 240 240 240 240 240 240 240
				240 240 240 240 240 240 240 240 240 240 240 240 240 240 240 240
				240 240 240 240 240 240 240 240 240 240 240 240 240 240 240 240
				240 240 240 240 240 240 240 240 240 240 240 240 240 240 240 240
				240 240 240 240 240 240 240 240 240 240 240 240 240 240 240 240
				240 240 240 240 240 240 240 240 240 240 240 240 240 240 240 240
				240 240 240 240 240 240 240 240 240 240 240 240 240 240 240 240
				240 240 240 240 240 240 240 240 240 240 240 240 240 240 240 240
				240 240 240 240 240 240 240 240 240 240 240 240 240 240 240 240
				240 240 240 240 240 240 240 240 240 240 240 240 240 240 240 240
				240 240 240 240 240 240 240 240 240 240 240 240 240 240 240 240
				240 240 240 240 240 240 240 240 240 240 240 240 240 240 240 240
				240 240 240 240 240 240 240 240 240 240 240 240 240 240 240 240
				240 240 240 240 240 240 240 240 240 240 240 240 240 240 240 240
				240 240 240 240 240 240 240 240 240 240 240 240 240 240 240 240
				240 240 240 240 240 240 240 240 240 240 240 240 240 240 240 240
				240 240 240 240 240 240 240 240 240 240 240 240 240 240 240 240
				240 240 240 240 240 240 240 240 240 240 240 240 240 240 240 240
				240 240 240 240 240 240 240 240 240 240 240 240 240 240 240 240
				240 240 240 240 240 240 240 240 240 240 240 240 240 240 240 240
				240 240 240 240 240 240 240 240 240 240 240 240 240 240 240 240
				>;

			PS_Config_Lmt_FW_CC_P = <
				314 314 314 314 314 314 314 314 314 314 314 314 314 314 314 314
				314 314 314 314 314 314 314 314 314 314 314 314 314 314 314 314
				314 314 314 314 314 314 314 314 314 314 314 314 314 314 314 314
				314 314 314 314 314 314 314 314 314 314 314 314 314 314 314 314
				314 314 314 314 314 314 314 314 314 314 314 314 314 314 314 314
				314 314 314 314 314 314 314 314 314 314 314 314 314 314 314 314
				314 314 314 314 314 314 314 314 314 314 314 314 314 314 314 314
				314 314 314 314 314 314 314 314 314 314 314 314 314 314 314 314
				314 314 314 314 314 314 314 314 314 314 314 314 314 314 314 314
				314 314 314 314 314 314 314 314 314 314 314 314 314 314 314 314
				314 314 314 314 314 314 314 314 314 314 314 314 314 314 314 314
				314 314 314 314 314 314 314 314 314 314 314 314 314 314 314 314
				314 314 314 314 314 314 314 314 314 314 314 314 314 314 314 314
				314 314 314 314 314 314 314 314 314 314 314 314 314 314 314 314
				314 314 314 314 314 314 314 314 314 314 314 314 314 314 314 314
				314 314 314 314 314 314 314 314 314 314 314 314 314 314 314 314
				314 314 314 314 314 314 314 314 314 314 314 314 314 314 314 314
				314 314 314 314 314 314 314 314 314 314 314 314 314 314 314 314
				314 314 314 314 314 314 314 314 314 314 314 314 314 314 314 314
				314 314 314 314 314 314 314 314 314 314 314 314 314 314 314 314
				314 314 314 314 314 314 314 314 314 314 314 314 314 314 314 314
				314 314 314 314 314 314 314 314 314 314 314 314 314 314 314 314
				314 314 314 314 314 314 314 314 314 314 314 314 314 314 314 314
				314 314 314 314 314 314 314 314 314 314 314 314 314 314 314 314
				314 314 314 314 314 314 314 314 314 314 314 314 314 314 314 314
				314 314 314 314 314 314 314 314 314 314 314 314 314 314 314 314
				314 314 314 314 314 314 314 314 314 314 314 314 314 314 314 314
				314 314 314 314 314 314 314 314 314 314 314 314 314 314 314 314
				314 314 314 314 314 314 314 314 314 314 314 314 314 314 314 314
				314 314 314 314 314 314 314 314 314 314 314 314 314 314 314 314
				314 314 314 314 314 314 314 314 314 314 314 314 314 314 314 314
				314 314 314 314 314 314 314 314 314 314 314 314 314 314 314 314
				314 314 314 314 314 314 314 314 314 314 314 314 314 314 314 314
				314 314 314 314 314 314 314 314 314 314 314 314 314 314 314 314
				314 314 314 314 314 314 314 314 314 314 314 314 314 314 314 314
				314 314 314 314 314 314 314 314 314 314 314 314 314 314 314 314
				>;

			PS_Config_Lmt_FW_CC_N = <
				0 0 0 0 0 0 0 0 0 0 0 0 0 0 0 0
				0 0 0 0 0 0 0 0 0 0 0 0 0 0 0 0
				0 0 0 0 0 0 0 0 0 0 0 0 0 0 0 0
				0 0 0 0 0 0 0 0 0 0 0 0 0 0 0 0
				0 0 0 0 0 0 0 0 0 0 0 0 0 0 0 0
				0 0 0 0 0 0 0 0 0 0 0 0 0 0 0 0
				0 0 0 0 0 0 0 0 0 0 0 0 0 0 0 0
				0 0 0 0 0 0 0 0 0 0 0 0 0 0 0 0
				0 0 0 0 0 0 0 0 0 0 0 0 0 0 0 0
				0 0 0 0 0 0 0 0 0 0 0 0 0 0 0 0
				0 0 0 0 0 0 0 0 0 0 0 0 0 0 0 0
				0 0 0 0 0 0 0 0 0 0 0 0 0 0 0 0
				0 0 0 0 0 0 0 0 0 0 0 0 0 0 0 0
				0 0 0 0 0 0 0 0 0 0 0 0 0 0 0 0
				0 0 0 0 0 0 0 0 0 0 0 0 0 0 0 0
				0 0 0 0 0 0 0 0 0 0 0 0 0 0 0 0
				0 0 0 0 0 0 0 0 0 0 0 0 0 0 0 0
				0 0 0 0 0 0 0 0 0 0 0 0 0 0 0 0
				0 0 0 0 0 0 0 0 0 0 0 0 0 0 0 0
				0 0 0 0 0 0 0 0 0 0 0 0 0 0 0 0
				0 0 0 0 0 0 0 0 0 0 0 0 0 0 0 0
				0 0 0 0 0 0 0 0 0 0 0 0 0 0 0 0
				0 0 0 0 0 0 0 0 0 0 0 0 0 0 0 0
				0 0 0 0 0 0 0 0 0 0 0 0 0 0 0 0
				0 0 0 0 0 0 0 0 0 0 0 0 0 0 0 0
				0 0 0 0 0 0 0 0 0 0 0 0 0 0 0 0
				0 0 0 0 0 0 0 0 0 0 0 0 0 0 0 0
				0 0 0 0 0 0 0 0 0 0 0 0 0 0 0 0
				0 0 0 0 0 0 0 0 0 0 0 0 0 0 0 0
				0 0 0 0 0 0 0 0 0 0 0 0 0 0 0 0
				0 0 0 0 0 0 0 0 0 0 0 0 0 0 0 0
				0 0 0 0 0 0 0 0 0 0 0 0 0 0 0 0
				0 0 0 0 0 0 0 0 0 0 0 0 0 0 0 0
				0 0 0 0 0 0 0 0 0 0 0 0 0 0 0 0
				0 0 0 0 0 0 0 0 0 0 0 0 0 0 0 0
				0 0 0 0 0 0 0 0 0 0 0 0 0 0 0 0
				>;

			PS_Config_Lmt_FW_Diff_P = <
				75 75 75 75 75 75 75 75 75 75 75 75 75 75 75 75
				75 75 75 75 75 75 75 75 75 75 75 75 75 75 75 75
				75 75 75 75 75 75 75 75 75 75 75 75 75 75 75 75
				75 75 75 75 75 75 75 75 75 75 75 75 75 75 75 75
				75 75 75 75 75 75 75 75 75 75 75 75 75 75 75 75
				75 75 75 75 75 75 75 75 75 75 75 75 75 75 75 75
				75 75 75 75 75 75 75 75 75 75 75 75 75 75 75 75
				75 75 75 75 75 75 75 75 75 75 75 75 75 75 75 75
				75 75 75 75 75 75 75 75 75 75 75 75 75 75 75 75
				75 75 75 75 75 75 75 75 75 75 75 75 75 75 75 75
				75 75 75 75 75 75 75 75 75 75 75 75 75 75 75 75
				75 75 75 75 75 75 75 75 75 75 75 75 75 75 75 75
				75 75 75 75 75 75 75 75 75 75 75 75 75 75 75 75
				75 75 75 75 75 75 75 75 75 75 75 75 75 75 75 75
				75 75 75 75 75 75 75 75 75 75 75 75 75 75 75 75
				75 75 75 75 75 75 75 75 75 75 75 75 75 75 75 75
				75 75 75 75 75 75 75 75 75 75 75 75 75 75 75 75
				75 75 75 75 75 75 75 75 75 75 75 75 75 75 75 75
				75 75 75 75 75 75 75 75 75 75 75 75 75 75 75 75
				75 75 75 75 75 75 75 75 75 75 75 75 75 75 75 75
				75 75 75 75 75 75 75 75 75 75 75 75 75 75 75 75
				75 75 75 75 75 75 75 75 75 75 75 75 75 75 75 75
				75 75 75 75 75 75 75 75 75 75 75 75 75 75 75 75
				75 75 75 75 75 75 75 75 75 75 75 75 75 75 75 75
				75 75 75 75 75 75 75 75 75 75 75 75 75 75 75 75
				75 75 75 75 75 75 75 75 75 75 75 75 75 75 75 75
				75 75 75 75 75 75 75 75 75 75 75 75 75 75 75 75
				75 75 75 75 75 75 75 75 75 75 75 75 75 75 75 75
				75 75 75 75 75 75 75 75 75 75 75 75 75 75 75 75
				75 75 75 75 75 75 75 75 75 75 75 75 75 75 75 75
				75 75 75 75 75 75 75 75 75 75 75 75 75 75 75 75
				75 75 75 75 75 75 75 75 75 75 75 75 75 75 75 75
				75 75 75 75 75 75 75 75 75 75 75 75 75 75 75 75
				75 75 75 75 75 75 75 75 75 75 75 75 75 75 75 75
				75 75 75 75 75 75 75 75 75 75 75 75 75 75 75 75
				75 75 75 75 75 75 75 75 75 75 75 75 75 75 75 75
				>;

			PS_Config_Lmt_FW_Diff_N = <
				(-75) (-75) (-75) (-75) (-75) (-75) (-75) (-75) (-75) (-75) (-75) (-75) (-75) (-75) (-75) (-75)
				(-75) (-75) (-75) (-75) (-75) (-75) (-75) (-75) (-75) (-75) (-75) (-75) (-75) (-75) (-75) (-75)
				(-75) (-75) (-75) (-75) (-75) (-75) (-75) (-75) (-75) (-75) (-75) (-75) (-75) (-75) (-75) (-75)
				(-75) (-75) (-75) (-75) (-75) (-75) (-75) (-75) (-75) (-75) (-75) (-75) (-75) (-75) (-75) (-75)
				(-75) (-75) (-75) (-75) (-75) (-75) (-75) (-75) (-75) (-75) (-75) (-75) (-75) (-75) (-75) (-75)
				(-75) (-75) (-75) (-75) (-75) (-75) (-75) (-75) (-75) (-75) (-75) (-75) (-75) (-75) (-75) (-75)
				(-75) (-75) (-75) (-75) (-75) (-75) (-75) (-75) (-75) (-75) (-75) (-75) (-75) (-75) (-75) (-75)
				(-75) (-75) (-75) (-75) (-75) (-75) (-75) (-75) (-75) (-75) (-75) (-75) (-75) (-75) (-75) (-75)
				(-75) (-75) (-75) (-75) (-75) (-75) (-75) (-75) (-75) (-75) (-75) (-75) (-75) (-75) (-75) (-75)
				(-75) (-75) (-75) (-75) (-75) (-75) (-75) (-75) (-75) (-75) (-75) (-75) (-75) (-75) (-75) (-75)
				(-75) (-75) (-75) (-75) (-75) (-75) (-75) (-75) (-75) (-75) (-75) (-75) (-75) (-75) (-75) (-75)
				(-75) (-75) (-75) (-75) (-75) (-75) (-75) (-75) (-75) (-75) (-75) (-75) (-75) (-75) (-75) (-75)
				(-75) (-75) (-75) (-75) (-75) (-75) (-75) (-75) (-75) (-75) (-75) (-75) (-75) (-75) (-75) (-75)
				(-75) (-75) (-75) (-75) (-75) (-75) (-75) (-75) (-75) (-75) (-75) (-75) (-75) (-75) (-75) (-75)
				(-75) (-75) (-75) (-75) (-75) (-75) (-75) (-75) (-75) (-75) (-75) (-75) (-75) (-75) (-75) (-75)
				(-75) (-75) (-75) (-75) (-75) (-75) (-75) (-75) (-75) (-75) (-75) (-75) (-75) (-75) (-75) (-75)
				(-75) (-75) (-75) (-75) (-75) (-75) (-75) (-75) (-75) (-75) (-75) (-75) (-75) (-75) (-75) (-75)
				(-75) (-75) (-75) (-75) (-75) (-75) (-75) (-75) (-75) (-75) (-75) (-75) (-75) (-75) (-75) (-75)
				(-75) (-75) (-75) (-75) (-75) (-75) (-75) (-75) (-75) (-75) (-75) (-75) (-75) (-75) (-75) (-75)
				(-75) (-75) (-75) (-75) (-75) (-75) (-75) (-75) (-75) (-75) (-75) (-75) (-75) (-75) (-75) (-75)
				(-75) (-75) (-75) (-75) (-75) (-75) (-75) (-75) (-75) (-75) (-75) (-75) (-75) (-75) (-75) (-75)
				(-75) (-75) (-75) (-75) (-75) (-75) (-75) (-75) (-75) (-75) (-75) (-75) (-75) (-75) (-75) (-75)
				(-75) (-75) (-75) (-75) (-75) (-75) (-75) (-75) (-75) (-75) (-75) (-75) (-75) (-75) (-75) (-75)
				(-75) (-75) (-75) (-75) (-75) (-75) (-75) (-75) (-75) (-75) (-75) (-75) (-75) (-75) (-75) (-75)
				(-75) (-75) (-75) (-75) (-75) (-75) (-75) (-75) (-75) (-75) (-75) (-75) (-75) (-75) (-75) (-75)
				(-75) (-75) (-75) (-75) (-75) (-75) (-75) (-75) (-75) (-75) (-75) (-75) (-75) (-75) (-75) (-75)
				(-75) (-75) (-75) (-75) (-75) (-75) (-75) (-75) (-75) (-75) (-75) (-75) (-75) (-75) (-75) (-75)
				(-75) (-75) (-75) (-75) (-75) (-75) (-75) (-75) (-75) (-75) (-75) (-75) (-75) (-75) (-75) (-75)
				(-75) (-75) (-75) (-75) (-75) (-75) (-75) (-75) (-75) (-75) (-75) (-75) (-75) (-75) (-75) (-75)
				(-75) (-75) (-75) (-75) (-75) (-75) (-75) (-75) (-75) (-75) (-75) (-75) (-75) (-75) (-75) (-75)
				(-75) (-75) (-75) (-75) (-75) (-75) (-75) (-75) (-75) (-75) (-75) (-75) (-75) (-75) (-75) (-75)
				(-75) (-75) (-75) (-75) (-75) (-75) (-75) (-75) (-75) (-75) (-75) (-75) (-75) (-75) (-75) (-75)
				(-75) (-75) (-75) (-75) (-75) (-75) (-75) (-75) (-75) (-75) (-75) (-75) (-75) (-75) (-75) (-75)
				(-75) (-75) (-75) (-75) (-75) (-75) (-75) (-75) (-75) (-75) (-75) (-75) (-75) (-75) (-75) (-75)
				(-75) (-75) (-75) (-75) (-75) (-75) (-75) (-75) (-75) (-75) (-75) (-75) (-75) (-75) (-75) (-75)
				(-75) (-75) (-75) (-75) (-75) (-75) (-75) (-75) (-75) (-75) (-75) (-75) (-75) (-75) (-75) (-75)
				>;

			PS_Config_Diff_Test_Frame = <50>;

			Doze_X_Channel = <2>;

			PS_Config_Lmt_Doze_Rawdata_P = <
				900 900
				900 900
				900 900
				900 900
				900 900
				900 900
				900 900
				900 900
				900 900
				900 900
				900 900
				900 900
				900 900
				900 900
				900 900
				900 900
				900 900
				900 900
				900 900
				900 900
				900 900
				900 900
				900 900
				900 900
				900 900
				900 900
				900 900
				900 900
				900 900
				900 900
				900 900
				900 900
				900 900
				900 900
				900 900
				900 900
				>;

			PS_Config_Lmt_Doze_Rawdata_N = <
				50 50
				50 50
				50 50
				50 50
				50 50
				50 50
				50 50
				50 50
				50 50
				50 50
				50 50
				50 50
				50 50
				50 50
				50 50
				50 50
				50 50
				50 50
				50 50
				50 50
				50 50
				50 50
				50 50
				50 50
				50 50
				50 50
				50 50
				50 50
				50 50
				50 50
				50 50
				50 50
				50 50
				50 50
				50 50
				50 50
				>;

			PS_Config_Doze_Noise_Test_Frame = <50>;

			PS_Config_Lmt_Doze_Diff_P = <
				80 80
				80 80
				80 80
				80 80
				80 80
				80 80
				80 80
				80 80
				80 80
				80 80
				80 80
				80 80
				80 80
				80 80
				80 80
				80 80
				80 80
				80 80
				80 80
				80 80
				80 80
				80 80
				80 80
				80 80
				80 80
				80 80
				80 80
				80 80
				80 80
				80 80
				80 80
				80 80
				80 80
				80 80
				80 80
				80 80
				>;

			PS_Config_Lmt_Doze_Diff_N = <
				(-80) (-80)
				(-80) (-80)
				(-80) (-80)
				(-80) (-80)
				(-80) (-80)
				(-80) (-80)
				(-80) (-80)
				(-80) (-80)
				(-80) (-80)
				(-80) (-80)
				(-80) (-80)
				(-80) (-80)
				(-80) (-80)
				(-80) (-80)
				(-80) (-80)
				(-80) (-80)
				(-80) (-80)
				(-80) (-80)
				(-80) (-80)
				(-80) (-80)
				(-80) (-80)
				(-80) (-80)
				(-80) (-80)
				(-80) (-80)
				(-80) (-80)
				(-80) (-80)
				(-80) (-80)
				(-80) (-80)
				(-80) (-80)
				(-80) (-80)
				(-80) (-80)
				(-80) (-80)
				(-80) (-80)
				(-80) (-80)
				(-80) (-80)
				(-80) (-80)
				>;

			PS_Config_Lmt_LPWG_Rawdata_P = <
				3840 3840 3840 3840 3840 3840 3840 3840 3840 3840 3840 3840 3840 3840 3840 3840
				3840 3840 3840 3840 3840 3840 3840 3840 3840 3840 3840 3840 3840 3840 3840 3840
				3840 3840 3840 3840 3840 3840 3840 3840 3840 3840 3840 3840 3840 3840 3840 3840
				3840 3840 3840 3840 3840 3840 3840 3840 3840 3840 3840 3840 3840 3840 3840 3840
				3840 3840 3840 3840 3840 3840 3840 3840 3840 3840 3840 3840 3840 3840 3840 3840
				3840 3840 3840 3840 3840 3840 3840 3840 3840 3840 3840 3840 3840 3840 3840 3840
				3840 3840 3840 3840 3840 3840 3840 3840 3840 3840 3840 3840 3840 3840 3840 3840
				3840 3840 3840 3840 3840 3840 3840 3840 3840 3840 3840 3840 3840 3840 3840 3840
				3840 3840 3840 3840 3840 3840 3840 3840 3840 3840 3840 3840 3840 3840 3840 3840
				3840 3840 3840 3840 3840 3840 3840 3840 3840 3840 3840 3840 3840 3840 3840 3840
				3840 3840 3840 3840 3840 3840 3840 3840 3840 3840 3840 3840 3840 3840 3840 3840
				3840 3840 3840 3840 3840 3840 3840 3840 3840 3840 3840 3840 3840 3840 3840 3840
				3840 3840 3840 3840 3840 3840 3840 3840 3840 3840 3840 3840 3840 3840 3840 3840
				3840 3840 3840 3840 3840 3840 3840 3840 3840 3840 3840 3840 3840 3840 3840 3840
				3840 3840 3840 3840 3840 3840 3840 3840 3840 3840 3840 3840 3840 3840 3840 3840
				3840 3840 3840 3840 3840 3840 3840 3840 3840 3840 3840 3840 3840 3840 3840 3840
				3840 3840 3840 3840 3840 3840 3840 3840 3840 3840 3840 3840 3840 3840 3840 3840
				3840 3840 3840 3840 3840 3840 3840 3840 3840 3840 3840 3840 3840 3840 3840 3840
				3840 3840 3840 3840 3840 3840 3840 3840 3840 3840 3840 3840 3840 3840 3840 3840
				3840 3840 3840 3840 3840 3840 3840 3840 3840 3840 3840 3840 3840 3840 3840 3840
				3840 3840 3840 3840 3840 3840 3840 3840 3840 3840 3840 3840 3840 3840 3840 3840
				3840 3840 3840 3840 3840 3840 3840 3840 3840 3840 3840 3840 3840 3840 3840 3840
				3840 3840 3840 3840 3840 3840 3840 3840 3840 3840 3840 3840 3840 3840 3840 3840
				3840 3840 3840 3840 3840 3840 3840 3840 3840 3840 3840 3840 3840 3840 3840 3840
				3840 3840 3840 3840 3840 3840 3840 3840 3840 3840 3840 3840 3840 3840 3840 3840
				3840 3840 3840 3840 3840 3840 3840 3840 3840 3840 3840 3840 3840 3840 3840 3840
				3840 3840 3840 3840 3840 3840 3840 3840 3840 3840 3840 3840 3840 3840 3840 3840
				3840 3840 3840 3840 3840 3840 3840 3840 3840 3840 3840 3840 3840 3840 3840 3840
				3840 3840 3840 3840 3840 3840 3840 3840 3840 3840 3840 3840 3840 3840 3840 3840
				3840 3840 3840 3840 3840 3840 3840 3840 3840 3840 3840 3840 3840 3840 3840 3840
				3840 3840 3840 3840 3840 3840 3840 3840 3840 3840 3840 3840 3840 3840 3840 3840
				3840 3840 3840 3840 3840 3840 3840 3840 3840 3840 3840 3840 3840 3840 3840 3840
				3840 3840 3840 3840 3840 3840 3840 3840 3840 3840 3840 3840 3840 3840 3840 3840
				3840 3840 3840 3840 3840 3840 3840 3840 3840 3840 3840 3840 3840 3840 3840 3840
				3840 3840 3840 3840 3840 3840 3840 3840 3840 3840 3840 3840 3840 3840 3840 3840
				3840 3840 3840 3840 3840 3840 3840 3840 3840 3840 3840 3840 3840 3840 3840 3840
				>;

			PS_Config_Lmt_LPWG_Rawdata_N = <
				240 240 240 240 240 240 240 240 240 240 240 240 240 240 240 240
				240 240 240 240 240 240 240 240 240 240 240 240 240 240 240 240
				240 240 240 240 240 240 240 240 240 240 240 240 240 240 240 240
				240 240 240 240 240 240 240 240 240 240 240 240 240 240 240 240
				240 240 240 240 240 240 240 240 240 240 240 240 240 240 240 240
				240 240 240 240 240 240 240 240 240 240 240 240 240 240 240 240
				240 240 240 240 240 240 240 240 240 240 240 240 240 240 240 240
				240 240 240 240 240 240 240 240 240 240 240 240 240 240 240 240
				240 240 240 240 240 240 240 240 240 240 240 240 240 240 240 240
				240 240 240 240 240 240 240 240 240 240 240 240 240 240 240 240
				240 240 240 240 240 240 240 240 240 240 240 240 240 240 240 240
				240 240 240 240 240 240 240 240 240 240 240 240 240 240 240 240
				240 240 240 240 240 240 240 240 240 240 240 240 240 240 240 240
				240 240 240 240 240 240 240 240 240 240 240 240 240 240 240 240
				240 240 240 240 240 240 240 240 240 240 240 240 240 240 240 240
				240 240 240 240 240 240 240 240 240 240 240 240 240 240 240 240
				240 240 240 240 240 240 240 240 240 240 240 240 240 240 240 240
				240 240 240 240 240 240 240 240 240 240 240 240 240 240 240 240
				240 240 240 240 240 240 240 240 240 240 240 240 240 240 240 240
				240 240 240 240 240 240 240 240 240 240 240 240 240 240 240 240
				240 240 240 240 240 240 240 240 240 240 240 240 240 240 240 240
				240 240 240 240 240 240 240 240 240 240 240 240 240 240 240 240
				240 240 240 240 240 240 240 240 240 240 240 240 240 240 240 240
				240 240 240 240 240 240 240 240 240 240 240 240 240 240 240 240
				240 240 240 240 240 240 240 240 240 240 240 240 240 240 240 240
				240 240 240 240 240 240 240 240 240 240 240 240 240 240 240 240
				240 240 240 240 240 240 240 240 240 240 240 240 240 240 240 240
				240 240 240 240 240 240 240 240 240 240 240 240 240 240 240 240
				240 240 240 240 240 240 240 240 240 240 240 240 240 240 240 240
				240 240 240 240 240 240 240 240 240 240 240 240 240 240 240 240
				240 240 240 240 240 240 240 240 240 240 240 240 240 240 240 240
				240 240 240 240 240 240 240 240 240 240 240 240 240 240 240 240
				240 240 240 240 240 240 240 240 240 240 240 240 240 240 240 240
				240 240 240 240 240 240 240 240 240 240 240 240 240 240 240 240
				240 240 240 240 240 240 240 240 240 240 240 240 240 240 240 240
				240 240 240 240 240 240 240 240 240 240 240 240 240 240 240 240
				>;

			PS_Config_Lmt_LPWG_Diff_P = <
				90 90 90 90 90 90 90 90 90 90 90 90 90 90 90 90
				90 90 90 90 90 90 90 90 90 90 90 90 90 90 90 90
				90 90 90 90 90 90 90 90 90 90 90 90 90 90 90 90
				90 90 90 90 90 90 90 90 90 90 90 90 90 90 90 90
				90 90 90 90 90 90 90 90 90 90 90 90 90 90 90 90
				90 90 90 90 90 90 90 90 90 90 90 90 90 90 90 90
				90 90 90 90 90 90 90 90 90 90 90 90 90 90 90 90
				90 90 90 90 90 90 90 90 90 90 90 90 90 90 90 90
				90 90 90 90 90 90 90 90 90 90 90 90 90 90 90 90
				90 90 90 90 90 90 90 90 90 90 90 90 90 90 90 90
				90 90 90 90 90 90 90 90 90 90 90 90 90 90 90 90
				90 90 90 90 90 90 90 90 90 90 90 90 90 90 90 90
				90 90 90 90 90 90 90 90 90 90 90 90 90 90 90 90
				90 90 90 90 90 90 90 90 90 90 90 90 90 90 90 90
				90 90 90 90 90 90 90 90 90 90 90 90 90 90 90 90
				90 90 90 90 90 90 90 90 90 90 90 90 90 90 90 90
				90 90 90 90 90 90 90 90 90 90 90 90 90 90 90 90
				90 90 90 90 90 90 90 90 90 90 90 90 90 90 90 90
				90 90 90 90 90 90 90 90 90 90 90 90 90 90 90 90
				90 90 90 90 90 90 90 90 90 90 90 90 90 90 90 90
				90 90 90 90 90 90 90 90 90 90 90 90 90 90 90 90
				90 90 90 90 90 90 90 90 90 90 90 90 90 90 90 90
				90 90 90 90 90 90 90 90 90 90 90 90 90 90 90 90
				90 90 90 90 90 90 90 90 90 90 90 90 90 90 90 90
				90 90 90 90 90 90 90 90 90 90 90 90 90 90 90 90
				90 90 90 90 90 90 90 90 90 90 90 90 90 90 90 90
				90 90 90 90 90 90 90 90 90 90 90 90 90 90 90 90
				90 90 90 90 90 90 90 90 90 90 90 90 90 90 90 90
				90 90 90 90 90 90 90 90 90 90 90 90 90 90 90 90
				90 90 90 90 90 90 90 90 90 90 90 90 90 90 90 90
				90 90 90 90 90 90 90 90 90 90 90 90 90 90 90 90
				90 90 90 90 90 90 90 90 90 90 90 90 90 90 90 90
				90 90 90 90 90 90 90 90 90 90 90 90 90 90 90 90
				90 90 90 90 90 90 90 90 90 90 90 90 90 90 90 90
				90 90 90 90 90 90 90 90 90 90 90 90 90 90 90 90
				90 90 90 90 90 90 90 90 90 90 90 90 90 90 90 90
				>;

			PS_Config_Lmt_LPWG_Diff_N = <
				(-90) (-90) (-90) (-90) (-90) (-90) (-90) (-90) (-90) (-90) (-90) (-90) (-90) (-90) (-90) (-90)
				(-90) (-90) (-90) (-90) (-90) (-90) (-90) (-90) (-90) (-90) (-90) (-90) (-90) (-90) (-90) (-90)
				(-90) (-90) (-90) (-90) (-90) (-90) (-90) (-90) (-90) (-90) (-90) (-90) (-90) (-90) (-90) (-90)
				(-90) (-90) (-90) (-90) (-90) (-90) (-90) (-90) (-90) (-90) (-90) (-90) (-90) (-90) (-90) (-90)
				(-90) (-90) (-90) (-90) (-90) (-90) (-90) (-90) (-90) (-90) (-90) (-90) (-90) (-90) (-90) (-90)
				(-90) (-90) (-90) (-90) (-90) (-90) (-90) (-90) (-90) (-90) (-90) (-90) (-90) (-90) (-90) (-90)
				(-90) (-90) (-90) (-90) (-90) (-90) (-90) (-90) (-90) (-90) (-90) (-90) (-90) (-90) (-90) (-90)
				(-90) (-90) (-90) (-90) (-90) (-90) (-90) (-90) (-90) (-90) (-90) (-90) (-90) (-90) (-90) (-90)
				(-90) (-90) (-90) (-90) (-90) (-90) (-90) (-90) (-90) (-90) (-90) (-90) (-90) (-90) (-90) (-90)
				(-90) (-90) (-90) (-90) (-90) (-90) (-90) (-90) (-90) (-90) (-90) (-90) (-90) (-90) (-90) (-90)
				(-90) (-90) (-90) (-90) (-90) (-90) (-90) (-90) (-90) (-90) (-90) (-90) (-90) (-90) (-90) (-90)
				(-90) (-90) (-90) (-90) (-90) (-90) (-90) (-90) (-90) (-90) (-90) (-90) (-90) (-90) (-90) (-90)
				(-90) (-90) (-90) (-90) (-90) (-90) (-90) (-90) (-90) (-90) (-90) (-90) (-90) (-90) (-90) (-90)
				(-90) (-90) (-90) (-90) (-90) (-90) (-90) (-90) (-90) (-90) (-90) (-90) (-90) (-90) (-90) (-90)
				(-90) (-90) (-90) (-90) (-90) (-90) (-90) (-90) (-90) (-90) (-90) (-90) (-90) (-90) (-90) (-90)
				(-90) (-90) (-90) (-90) (-90) (-90) (-90) (-90) (-90) (-90) (-90) (-90) (-90) (-90) (-90) (-90)
				(-90) (-90) (-90) (-90) (-90) (-90) (-90) (-90) (-90) (-90) (-90) (-90) (-90) (-90) (-90) (-90)
				(-90) (-90) (-90) (-90) (-90) (-90) (-90) (-90) (-90) (-90) (-90) (-90) (-90) (-90) (-90) (-90)
				(-90) (-90) (-90) (-90) (-90) (-90) (-90) (-90) (-90) (-90) (-90) (-90) (-90) (-90) (-90) (-90)
				(-90) (-90) (-90) (-90) (-90) (-90) (-90) (-90) (-90) (-90) (-90) (-90) (-90) (-90) (-90) (-90)
				(-90) (-90) (-90) (-90) (-90) (-90) (-90) (-90) (-90) (-90) (-90) (-90) (-90) (-90) (-90) (-90)
				(-90) (-90) (-90) (-90) (-90) (-90) (-90) (-90) (-90) (-90) (-90) (-90) (-90) (-90) (-90) (-90)
				(-90) (-90) (-90) (-90) (-90) (-90) (-90) (-90) (-90) (-90) (-90) (-90) (-90) (-90) (-90) (-90)
				(-90) (-90) (-90) (-90) (-90) (-90) (-90) (-90) (-90) (-90) (-90) (-90) (-90) (-90) (-90) (-90)
				(-90) (-90) (-90) (-90) (-90) (-90) (-90) (-90) (-90) (-90) (-90) (-90) (-90) (-90) (-90) (-90)
				(-90) (-90) (-90) (-90) (-90) (-90) (-90) (-90) (-90) (-90) (-90) (-90) (-90) (-90) (-90) (-90)
				(-90) (-90) (-90) (-90) (-90) (-90) (-90) (-90) (-90) (-90) (-90) (-90) (-90) (-90) (-90) (-90)
				(-90) (-90) (-90) (-90) (-90) (-90) (-90) (-90) (-90) (-90) (-90) (-90) (-90) (-90) (-90) (-90)
				(-90) (-90) (-90) (-90) (-90) (-90) (-90) (-90) (-90) (-90) (-90) (-90) (-90) (-90) (-90) (-90)
				(-90) (-90) (-90) (-90) (-90) (-90) (-90) (-90) (-90) (-90) (-90) (-90) (-90) (-90) (-90) (-90)
				(-90) (-90) (-90) (-90) (-90) (-90) (-90) (-90) (-90) (-90) (-90) (-90) (-90) (-90) (-90) (-90)
				(-90) (-90) (-90) (-90) (-90) (-90) (-90) (-90) (-90) (-90) (-90) (-90) (-90) (-90) (-90) (-90)
				(-90) (-90) (-90) (-90) (-90) (-90) (-90) (-90) (-90) (-90) (-90) (-90) (-90) (-90) (-90) (-90)
				(-90) (-90) (-90) (-90) (-90) (-90) (-90) (-90) (-90) (-90) (-90) (-90) (-90) (-90) (-90) (-90)
				(-90) (-90) (-90) (-90) (-90) (-90) (-90) (-90) (-90) (-90) (-90) (-90) (-90) (-90) (-90) (-90)
				(-90) (-90) (-90) (-90) (-90) (-90) (-90) (-90) (-90) (-90) (-90) (-90) (-90) (-90) (-90) (-90)
				>;

			FDM_X_Channel = <2>;

			PS_Config_Lmt_FDM_Rawdata_P = <
				900 900
				900 900
				900 900
				900 900
				900 900
				900 900
				900 900
				900 900
				900 900
				900 900
				900 900
				900 900
				900 900
				900 900
				900 900
				900 900
				900 900
				900 900
				900 900
				900 900
				900 900
				900 900
				900 900
				900 900
				900 900
				900 900
				900 900
				900 900
				900 900
				900 900
				900 900
				900 900
				900 900
				900 900
				900 900
				900 900
				>;

			PS_Config_Lmt_FDM_Rawdata_N = <
				50 50
				50 50
				50 50
				50 50
				50 50
				50 50
				50 50
				50 50
				50 50
				50 50
				50 50
				50 50
				50 50
				50 50
				50 50
				50 50
				50 50
				50 50
				50 50
				50 50
				50 50
				50 50
				50 50
				50 50
				50 50
				50 50
				50 50
				50 50
				50 50
				50 50
				50 50
				50 50
				50 50
				50 50
				50 50
				50 50
				>;

			PS_Config_FDM_Noise_Test_Frame = <50>;

			PS_Config_Lmt_FDM_Diff_P = <
				260 260
				260 260
				260 260
				260 260
				260 260
				260 260
				260 260
				260 260
				260 260
				260 260
				260 260
				260 260
				260 260
				260 260
				260 260
				260 260
				260 260
				260 260
				260 260
				260 260
				260 260
				260 260
				260 260
				260 260
				260 260
				260 260
				260 260
				260 260
				260 260
				260 260
				260 260
				260 260
				260 260
				260 260
				260 260
				260 260
				>;

			PS_Config_Lmt_FDM_Diff_N = <
				(-260) (-260)
				(-260) (-260)
				(-260) (-260)
				(-260) (-260)
				(-260) (-260)
				(-260) (-260)
				(-260) (-260)
				(-260) (-260)
				(-260) (-260)
				(-260) (-260)
				(-260) (-260)
				(-260) (-260)
				(-260) (-260)
				(-260) (-260)
				(-260) (-260)
				(-260) (-260)
				(-260) (-260)
				(-260) (-260)
				(-260) (-260)
				(-260) (-260)
				(-260) (-260)
				(-260) (-260)
				(-260) (-260)
				(-260) (-260)
				(-260) (-260)
				(-260) (-260)
				(-260) (-260)
				(-260) (-260)
				(-260) (-260)
				(-260) (-260)
				(-260) (-260)
				(-260) (-260)
				(-260) (-260)
				(-260) (-260)
				(-260) (-260)
				(-260) (-260)
				>;

			PS_Config_Lmt_FW_DigiDiff_P = <
				75 75 75 75 75 75 75 75 75 75 75 75 75 75 75 75
				75 75 75 75 75 75 75 75 75 75 75 75 75 75 75 75
				75 75 75 75 75 75 75 75 75 75 75 75 75 75 75 75
				75 75 75 75 75 75 75 75 75 75 75 75 75 75 75 75
				75 75 75 75 75 75 75 75 75 75 75 75 75 75 75 75
				75 75 75 75 75 75 75 75 75 75 75 75 75 75 75 75
				75 75 75 75 75 75 75 75 75 75 75 75 75 75 75 75
				75 75 75 75 75 75 75 75 75 75 75 75 75 75 75 75
				75 75 75 75 75 75 75 75 75 75 75 75 75 75 75 75
				75 75 75 75 75 75 75 75 75 75 75 75 75 75 75 75
				75 75 75 75 75 75 75 75 75 75 75 75 75 75 75 75
				75 75 75 75 75 75 75 75 75 75 75 75 75 75 75 75
				75 75 75 75 75 75 75 75 75 75 75 75 75 75 75 75
				75 75 75 75 75 75 75 75 75 75 75 75 75 75 75 75
				75 75 75 75 75 75 75 75 75 75 75 75 75 75 75 75
				75 75 75 75 75 75 75 75 75 75 75 75 75 75 75 75
				75 75 75 75 75 75 75 75 75 75 75 75 75 75 75 75
				75 75 75 75 75 75 75 75 75 75 75 75 75 75 75 75
				75 75 75 75 75 75 75 75 75 75 75 75 75 75 75 75
				75 75 75 75 75 75 75 75 75 75 75 75 75 75 75 75
				75 75 75 75 75 75 75 75 75 75 75 75 75 75 75 75
				75 75 75 75 75 75 75 75 75 75 75 75 75 75 75 75
				75 75 75 75 75 75 75 75 75 75 75 75 75 75 75 75
				75 75 75 75 75 75 75 75 75 75 75 75 75 75 75 75
				75 75 75 75 75 75 75 75 75 75 75 75 75 75 75 75
				75 75 75 75 75 75 75 75 75 75 75 75 75 75 75 75
				75 75 75 75 75 75 75 75 75 75 75 75 75 75 75 75
				75 75 75 75 75 75 75 75 75 75 75 75 75 75 75 75
				75 75 75 75 75 75 75 75 75 75 75 75 75 75 75 75
				75 75 75 75 75 75 75 75 75 75 75 75 75 75 75 75
				75 75 75 75 75 75 75 75 75 75 75 75 75 75 75 75
				75 75 75 75 75 75 75 75 75 75 75 75 75 75 75 75
				75 75 75 75 75 75 75 75 75 75 75 75 75 75 75 75
				75 75 75 75 75 75 75 75 75 75 75 75 75 75 75 75
				75 75 75 75 75 75 75 75 75 75 75 75 75 75 75 75
				75 75 75 75 75 75 75 75 75 75 75 75 75 75 75 75
				>;

			PS_Config_Lmt_FW_DigiDiff_N = <
				(-75) (-75) (-75) (-75) (-75) (-75) (-75) (-75) (-75) (-75) (-75) (-75) (-75) (-75) (-75) (-75)
				(-75) (-75) (-75) (-75) (-75) (-75) (-75) (-75) (-75) (-75) (-75) (-75) (-75) (-75) (-75) (-75)
				(-75) (-75) (-75) (-75) (-75) (-75) (-75) (-75) (-75) (-75) (-75) (-75) (-75) (-75) (-75) (-75)
				(-75) (-75) (-75) (-75) (-75) (-75) (-75) (-75) (-75) (-75) (-75) (-75) (-75) (-75) (-75) (-75)
				(-75) (-75) (-75) (-75) (-75) (-75) (-75) (-75) (-75) (-75) (-75) (-75) (-75) (-75) (-75) (-75)
				(-75) (-75) (-75) (-75) (-75) (-75) (-75) (-75) (-75) (-75) (-75) (-75) (-75) (-75) (-75) (-75)
				(-75) (-75) (-75) (-75) (-75) (-75) (-75) (-75) (-75) (-75) (-75) (-75) (-75) (-75) (-75) (-75)
				(-75) (-75) (-75) (-75) (-75) (-75) (-75) (-75) (-75) (-75) (-75) (-75) (-75) (-75) (-75) (-75)
				(-75) (-75) (-75) (-75) (-75) (-75) (-75) (-75) (-75) (-75) (-75) (-75) (-75) (-75) (-75) (-75)
				(-75) (-75) (-75) (-75) (-75) (-75) (-75) (-75) (-75) (-75) (-75) (-75) (-75) (-75) (-75) (-75)
				(-75) (-75) (-75) (-75) (-75) (-75) (-75) (-75) (-75) (-75) (-75) (-75) (-75) (-75) (-75) (-75)
				(-75) (-75) (-75) (-75) (-75) (-75) (-75) (-75) (-75) (-75) (-75) (-75) (-75) (-75) (-75) (-75)
				(-75) (-75) (-75) (-75) (-75) (-75) (-75) (-75) (-75) (-75) (-75) (-75) (-75) (-75) (-75) (-75)
				(-75) (-75) (-75) (-75) (-75) (-75) (-75) (-75) (-75) (-75) (-75) (-75) (-75) (-75) (-75) (-75)
				(-75) (-75) (-75) (-75) (-75) (-75) (-75) (-75) (-75) (-75) (-75) (-75) (-75) (-75) (-75) (-75)
				(-75) (-75) (-75) (-75) (-75) (-75) (-75) (-75) (-75) (-75) (-75) (-75) (-75) (-75) (-75) (-75)
				(-75) (-75) (-75) (-75) (-75) (-75) (-75) (-75) (-75) (-75) (-75) (-75) (-75) (-75) (-75) (-75)
				(-75) (-75) (-75) (-75) (-75) (-75) (-75) (-75) (-75) (-75) (-75) (-75) (-75) (-75) (-75) (-75)
				(-75) (-75) (-75) (-75) (-75) (-75) (-75) (-75) (-75) (-75) (-75) (-75) (-75) (-75) (-75) (-75)
				(-75) (-75) (-75) (-75) (-75) (-75) (-75) (-75) (-75) (-75) (-75) (-75) (-75) (-75) (-75) (-75)
				(-75) (-75) (-75) (-75) (-75) (-75) (-75) (-75) (-75) (-75) (-75) (-75) (-75) (-75) (-75) (-75)
				(-75) (-75) (-75) (-75) (-75) (-75) (-75) (-75) (-75) (-75) (-75) (-75) (-75) (-75) (-75) (-75)
				(-75) (-75) (-75) (-75) (-75) (-75) (-75) (-75) (-75) (-75) (-75) (-75) (-75) (-75) (-75) (-75)
				(-75) (-75) (-75) (-75) (-75) (-75) (-75) (-75) (-75) (-75) (-75) (-75) (-75) (-75) (-75) (-75)
				(-75) (-75) (-75) (-75) (-75) (-75) (-75) (-75) (-75) (-75) (-75) (-75) (-75) (-75) (-75) (-75)
				(-75) (-75) (-75) (-75) (-75) (-75) (-75) (-75) (-75) (-75) (-75) (-75) (-75) (-75) (-75) (-75)
				(-75) (-75) (-75) (-75) (-75) (-75) (-75) (-75) (-75) (-75) (-75) (-75) (-75) (-75) (-75) (-75)
				(-75) (-75) (-75) (-75) (-75) (-75) (-75) (-75) (-75) (-75) (-75) (-75) (-75) (-75) (-75) (-75)
				(-75) (-75) (-75) (-75) (-75) (-75) (-75) (-75) (-75) (-75) (-75) (-75) (-75) (-75) (-75) (-75)
				(-75) (-75) (-75) (-75) (-75) (-75) (-75) (-75) (-75) (-75) (-75) (-75) (-75) (-75) (-75) (-75)
				(-75) (-75) (-75) (-75) (-75) (-75) (-75) (-75) (-75) (-75) (-75) (-75) (-75) (-75) (-75) (-75)
				(-75) (-75) (-75) (-75) (-75) (-75) (-75) (-75) (-75) (-75) (-75) (-75) (-75) (-75) (-75) (-75)
				(-75) (-75) (-75) (-75) (-75) (-75) (-75) (-75) (-75) (-75) (-75) (-75) (-75) (-75) (-75) (-75)
				(-75) (-75) (-75) (-75) (-75) (-75) (-75) (-75) (-75) (-75) (-75) (-75) (-75) (-75) (-75) (-75)
				(-75) (-75) (-75) (-75) (-75) (-75) (-75) (-75) (-75) (-75) (-75) (-75) (-75) (-75) (-75) (-75)
				(-75) (-75) (-75) (-75) (-75) (-75) (-75) (-75) (-75) (-75) (-75) (-75) (-75) (-75) (-75) (-75)
				>;
		};
	};
};

&dvfs_dcdc_cpu0_cfg {
	pmic-type-num = <0>;
	slew-rate = <9375>; /* 9375uV/us */
	tuning-latency-us = <0>;
};

&dvfs_dcdc_cpu1_cfg {
	chnl-i2c-used;
	third-pmic-used;
	pmic-type-num = <2>;
	slew-rate = <4000>; /* 4000uV/us */
	tuning-latency-us = <0>;
};

&dvfs_dcdc_cpu1_cfg1 {
	third-pmic-used;
	pmic-type-num = <0>;
	slew-rate = <9375>; /* 9375uV/us */
	tuning-latency-us = <0>;
};

&hsphy {
	vdd-supply = <&vddusb33>;
	extcon = <&extcon_gpio>;
	sprd,hsphy-device-eye-pattern = <0x04f3d1c0>;
	sprd,hsphy-host-eye-pattern = <0x04f3d1c0>;
	status = "okay";
};

&usb {
	extcon = <&extcon_gpio>, <&pmic_typec>;
	vbus-supply = <&vddvbus>;
	status = "okay";
};

&sdio0 {
	cd-gpios = <&eic_sync 35 GPIO_ACTIVE_HIGH>;
};


&sdio1 {
	sprd,phy-delay-sd-uhs-sdr104 = <0x7f 0x7f 0x7f 0x7f>;
	sprd,phy-delay-sd-uhs-sdr50 = <0x7f 0x7f 0x8f 0x8f>;
	sd-uhs-sdr104;
	sd-uhs-sdr50;
	bus-width = <4>;
	sprd,name = "sdio_wifi";
	sprd,sdio-adma;
	no-sd;
	no-mmc;
	status = "okay";
};

&i2c2 {
    status = "okay";
};

&i2c3 {
    status = "okay";
};

&i2c4 {
    status = "okay";
	clock-frequency = <400000>;
	#address-cells = <1>;
	#size-cells = <0>;

    /* add your dts node */
    lcd_bias_voltage_adjust@3e {
        compatible = "sprd,lcm_bias";
        reg = <0x3e>;
    };
};

&aon_i2c0 {
	status = "okay";
	clock-frequency = <1000000>;
};

&sprd_headset {
    status = "okay";
};

&pdm_dmic {
	status = "okay";
};

&sound_vbc_v4_sprd_codec {
    status = "okay";
    /*ext_control_type, hook selection, mode, gpio share*/
    sprd,spk-ext-pa-info = <0 0 1 0>;
    sprd,spk-ext-pa-gpio = <&ap_gpio 129 0>;
    sprd,spk-ext-pa-det = <&ap_gpio 46 0>;
};



&vddldo0 {
	regulator-always-on;
};

&pmic_fgu {
	monitored-battery = <&bat>;
	sprd,calib-resistance-micro-ohms = <4850>;
	sprd,comp-resistance-mohm = <10>;

	fgu-capacity-track;
	phys = <&hsphy>;
};

&panel {
	avdd-gpio = <&ap_gpio 135 GPIO_ACTIVE_HIGH>;
	avee-gpio = <&ap_gpio 136 GPIO_ACTIVE_HIGH>;
	reset-gpio = <&ap_gpio 50 GPIO_ACTIVE_HIGH>;
};

&dpu {
	sprd,logo-memory = <&logo_reserved>;
};

&lcd_g40396_truly_mipi_fhd {
	display-timings {
		g40396_truly_timing1: timing1 {
			clock-frequency = <192000000>;
			hactive = <720>;
			vactive = <1600>;
			hback-porch = <75>;
			hfront-porch = <75>;
			vback-porch = <32>;
			vfront-porch = <8>;
			hsync-len = <75>;
			vsync-len = <8>;
		};
	};
};

&lcd_NT36672C_tm_mipi_hd {
	display-timings {
		NT36672C_tm_timing1: timing1 {
			clock-frequency = <193000000>;
			hactive = <1080>;
			vactive = <2408>;
			hback-porch = <68>;
			hfront-porch = <132>;
			vback-porch = <54>;
			vfront-porch = <620>;
			hsync-len = <16>;
			vsync-len = <8>;
		};
		NT36672C_tm_timing2: timing2 {
			clock-frequency = <193000000>;
			hactive = <1080>;
			vactive = <2408>;
			hback-porch = <68>;
			hfront-porch = <132>;
			vback-porch = <54>;
			vfront-porch = <500>;
			hsync-len = <16>;
			vsync-len = <8>;
		};
		NT36672C_tm_timing3: timing3 {
			clock-frequency = <193000000>;
			hactive = <1080>;
			vactive = <2408>;
			hback-porch = <68>;
			hfront-porch = <132>;
			vback-porch = <54>;
			vfront-porch = <12>;
			hsync-len = <16>;
			vsync-len = <8>;
		};
	};
};

&lcd_NT36672C_csot_mipi_hd {
	display-timings {
		NT36672C_csot_timing1: timing1 {
			clock-frequency = <193000000>;
			hactive = <1080>;
			vactive = <2408>;
			hback-porch = <68>;
			hfront-porch = <132>;
			vback-porch = <54>;
			vfront-porch = <620>;
			hsync-len = <16>;
			vsync-len = <8>;
		};
		NT36672C_csot_timing2: timing2 {
			clock-frequency = <193000000>;
			hactive = <1080>;
			vactive = <2408>;
			hback-porch = <68>;
			hfront-porch = <132>;
			vback-porch = <54>;
			vfront-porch = <500>;
			hsync-len = <16>;
			vsync-len = <8>;
		};
		NT36672C_csot_timing3: timing3 {
			clock-frequency = <193000000>;
			hactive = <1080>;
			vactive = <2408>;
			hback-porch = <68>;
			hfront-porch = <132>;
			vback-porch = <54>;
			vfront-porch = <12>;
			hsync-len = <16>;
			vsync-len = <8>;
		};
	};
};

&pmic_fchg {
	status = "okay";
	sprd,input-voltage-microvolt = <5000000>;
	sprd,pd-fixed-max-microwatt = <18000000>;
	sprd,support-sfcp;
	sprd,support-pd-pps;
	phys = <&hsphy>;
};

&pmic_pd {
	status = "okay";
	usb_con: connector {
		compatible = "usb-c-connector";
		label = "USB-C";
		power-role = "dual";
		try-power-role = "sink";
		source-pdos = <PDO_FIXED(5000, 400, PDO_FIXED_USB_COMM)>;
		sink-pdos = <PDO_FIXED(5000, 3000, PDO_FIXED_USB_COMM)
			     PDO_PPS_APDO(3300, 11000, 3000)>;
		op-sink-microwatt = <10000000>;
	};
};

&ddr_dfs {
	  sprd-scene = "boost", "lcdon", "lcdoff", "camlow",
			"camhigh", "camveryhigh", "faceid", "top";
	  sprd-freq = <1333 768 256 1333 1333 0xbacd 1333 0xbacd>;
};

&pin_controller {
	pinctrl-names =
	/* rfctl16 ,rfctl3, rfctl5 */
	"gpio_8", "gpio_22", "gpio_24",
	/* rfctl6, rfctl7, keyin0 */
	"gpio_25", "gpio_26", "gpio_124",
	/* bt_rfctl2 */
	"gpio_175";
	pinctrl-0 = <&gpio_8>;
	pinctrl-1 = <&gpio_22>;
	pinctrl-2 = <&gpio_24>;
	pinctrl-3 = <&gpio_25>;
	pinctrl-4 = <&gpio_26>;
	pinctrl-5 = <&gpio_124>;
	pinctrl-6 = <&gpio_175>;

	gpio_8: rfctl16 {
		pins = "QOGIRL6_RFCTL16";
		function = "func4";
	};

	gpio_22: rfctl3 {
		pins = "QOGIRL6_RFCTL3";
		function = "func4";
	};

	gpio_24: rfctl5 {
		pins = "QOGIRL6_RFCTL5";
		function = "func4";
	};

	gpio_25: rfctl6 {
		pins = "QOGIRL6_RFCTL6";
		function = "func4";
	};

	gpio_26: rfctl7 {
		pins = "QOGIRL6_RFCTL7";
		function = "func4";
	};

	gpio_124: keyin0 {
		pins = "QOGIRL6_KEYIN0";
		function = "func4";
	};

	gpio_175: bt_rfctl2 {
		pins = "QOGIRL6_BT_RFCTL2";
		function = "func4";
	};
};

&ion {
	#address-cells = <1>;
	#size-cells = <0>;

	heap@1 {
		reg = <1>;
		label = "carveout_mm";
		type = <2>;
		memory-region = <&widevine_reserved>;
	};

	heap@4 {
		reg = <4>;
		label = "carveout_fd";
		type = <2>;
		memory-region = <&fd_reserved>;
	};
};

&adi_bus {
	sprd,hw-channels0 = <2 0x18cc>, <3 0x18cc>, <13 0x1874>, <15 0x1874>,
			<17 0x1844>, <19 0x1854>, <21 0x1864>, <30 0x1820>,
			<32 0x197c>, <33 0x1988>, <35 0x19b8>, <39 0x19ac>;
	sprd,hw-channels1 = <2 0x18cc>, <3 0x18cc>, <13 0x1854>, <15 0x1874>,
			<17 0x1844>, <19 0x1844>, <21 0x1864>, <30 0x1820>,
			<32 0x197c>, <33 0x1988>, <35 0x19b8>, <39 0x19ac>;
};
